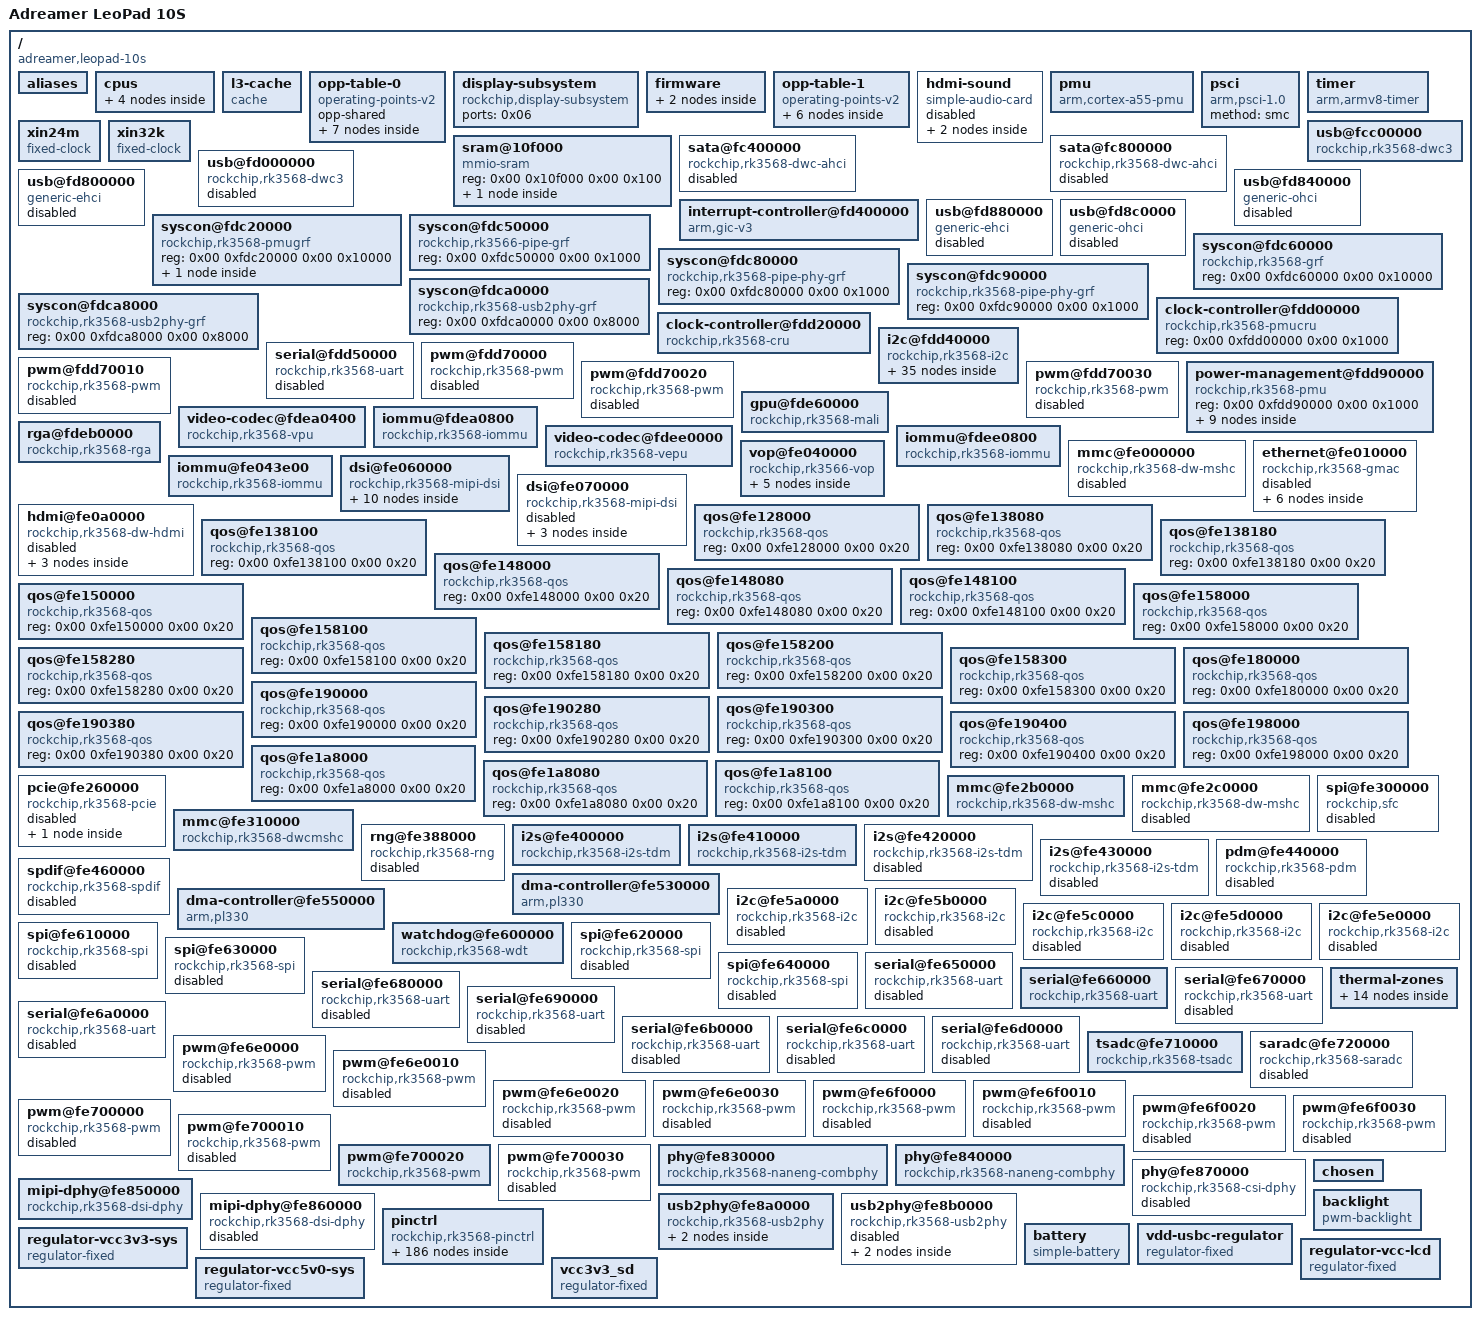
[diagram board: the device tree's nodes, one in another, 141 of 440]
/dts-v1/;

/ {
	interrupt-parent = <0x01>;
	#address-cells = <0x02>;
	#size-cells = <0x02>;
	compatible = "adreamer,leopad-10s\0rockchip,rk3566";
	model = "Adreamer LeoPad 10S";

	aliases {
		gpio0 = "/pinctrl/gpio@fdd60000";
		gpio1 = "/pinctrl/gpio@fe740000";
		gpio2 = "/pinctrl/gpio@fe750000";
		gpio3 = "/pinctrl/gpio@fe760000";
		gpio4 = "/pinctrl/gpio@fe770000";
		i2c0 = "/i2c@fdd40000";
		i2c1 = "/i2c@fe5a0000";
		i2c2 = "/i2c@fe5b0000";
		i2c3 = "/i2c@fe5c0000";
		i2c4 = "/i2c@fe5d0000";
		i2c5 = "/i2c@fe5e0000";
		serial0 = "/serial@fdd50000";
		serial1 = "/serial@fe650000";
		serial2 = "/serial@fe660000";
		serial3 = "/serial@fe670000";
		serial4 = "/serial@fe680000";
		serial5 = "/serial@fe690000";
		serial6 = "/serial@fe6a0000";
		serial7 = "/serial@fe6b0000";
		serial8 = "/serial@fe6c0000";
		serial9 = "/serial@fe6d0000";
		spi0 = "/spi@fe610000";
		spi1 = "/spi@fe620000";
		spi2 = "/spi@fe630000";
		spi3 = "/spi@fe640000";
		mmc0 = "/mmc@fe2b0000";
		mmc1 = "/mmc@fe310000";
	};

	cpus {
		#address-cells = <0x02>;
		#size-cells = <0x00>;

		cpu@0 {
			device_type = "cpu";
			compatible = "arm,cortex-a55";
			reg = <0x00 0x00>;
			clocks = <0x02 0x00>;
			#cooling-cells = <0x02>;
			enable-method = "psci";
			operating-points-v2 = <0x03>;
			i-cache-size = <0x8000>;
			i-cache-line-size = <0x40>;
			i-cache-sets = <0x80>;
			d-cache-size = <0x8000>;
			d-cache-line-size = <0x40>;
			d-cache-sets = <0x80>;
			next-level-cache = <0x04>;
			cpu-supply = <0x05>;
			phandle = <0x0a>;
		};

		cpu@100 {
			device_type = "cpu";
			compatible = "arm,cortex-a55";
			reg = <0x00 0x100>;
			#cooling-cells = <0x02>;
			enable-method = "psci";
			operating-points-v2 = <0x03>;
			i-cache-size = <0x8000>;
			i-cache-line-size = <0x40>;
			i-cache-sets = <0x80>;
			d-cache-size = <0x8000>;
			d-cache-line-size = <0x40>;
			d-cache-sets = <0x80>;
			next-level-cache = <0x04>;
			cpu-supply = <0x05>;
			phandle = <0x0b>;
		};

		cpu@200 {
			device_type = "cpu";
			compatible = "arm,cortex-a55";
			reg = <0x00 0x200>;
			#cooling-cells = <0x02>;
			enable-method = "psci";
			operating-points-v2 = <0x03>;
			i-cache-size = <0x8000>;
			i-cache-line-size = <0x40>;
			i-cache-sets = <0x80>;
			d-cache-size = <0x8000>;
			d-cache-line-size = <0x40>;
			d-cache-sets = <0x80>;
			next-level-cache = <0x04>;
			cpu-supply = <0x05>;
			phandle = <0x0c>;
		};

		cpu@300 {
			device_type = "cpu";
			compatible = "arm,cortex-a55";
			reg = <0x00 0x300>;
			#cooling-cells = <0x02>;
			enable-method = "psci";
			operating-points-v2 = <0x03>;
			i-cache-size = <0x8000>;
			i-cache-line-size = <0x40>;
			i-cache-sets = <0x80>;
			d-cache-size = <0x8000>;
			d-cache-line-size = <0x40>;
			d-cache-sets = <0x80>;
			next-level-cache = <0x04>;
			cpu-supply = <0x05>;
			phandle = <0x0d>;
		};
	};

	l3-cache {
		compatible = "cache";
		cache-level = <0x02>;
		cache-unified;
		cache-size = <0x80000>;
		cache-line-size = <0x40>;
		cache-sets = <0x200>;
		phandle = <0x04>;
	};

	opp-table-0 {
		compatible = "operating-points-v2";
		opp-shared;
		phandle = <0x03>;

		opp-408000000 {
			opp-hz = <0x00 0x18519600>;
			opp-microvolt = <0xdbba0 0xdbba0 0x118c30>;
			clock-latency-ns = <0x9c40>;
		};

		opp-600000000 {
			opp-hz = <0x00 0x23c34600>;
			opp-microvolt = <0xdbba0 0xdbba0 0x118c30>;
		};

		opp-816000000 {
			opp-hz = <0x00 0x30a32c00>;
			opp-microvolt = <0xdbba0 0xdbba0 0x118c30>;
			opp-suspend;
		};

		opp-1104000000 {
			opp-hz = <0x00 0x41cdb400>;
			opp-microvolt = <0xdbba0 0xdbba0 0x118c30>;
		};

		opp-1416000000 {
			opp-hz = <0x00 0x54667200>;
			opp-microvolt = <0xdbba0 0xdbba0 0x118c30>;
		};

		opp-1608000000 {
			opp-hz = <0x00 0x5fd82200>;
			opp-microvolt = <0xee098 0xee098 0x118c30>;
		};

		opp-1800000000 {
			opp-hz = <0x00 0x6b49d200>;
			opp-microvolt = <0x100590 0x100590 0x118c30>;
		};
	};

	display-subsystem {
		compatible = "rockchip,display-subsystem";
		ports = <0x06>;
	};

	firmware {

		scmi {
			compatible = "arm,scmi-smc";
			arm,smc-id = <0x82000010>;
			shmem = <0x07>;
			#address-cells = <0x01>;
			#size-cells = <0x00>;

			protocol@14 {
				reg = <0x14>;
				#clock-cells = <0x01>;
				phandle = <0x02>;
			};
		};
	};

	opp-table-1 {
		compatible = "operating-points-v2";
		phandle = <0x46>;

		opp-200000000 {
			opp-hz = <0x00 0xbebc200>;
			opp-microvolt = <0xc96a8>;
		};

		opp-300000000 {
			opp-hz = <0x00 0x11e1a300>;
			opp-microvolt = <0xc96a8>;
		};

		opp-400000000 {
			opp-hz = <0x00 0x17d78400>;
			opp-microvolt = <0xc96a8>;
		};

		opp-600000000 {
			opp-hz = <0x00 0x23c34600>;
			opp-microvolt = <0xc96a8>;
		};

		opp-700000000 {
			opp-hz = <0x00 0x29b92700>;
			opp-microvolt = <0xdbba0>;
		};

		opp-800000000 {
			opp-hz = <0x00 0x2faf0800>;
			opp-microvolt = <0xf4240>;
		};
	};

	hdmi-sound {
		compatible = "simple-audio-card";
		simple-audio-card,name = "HDMI";
		simple-audio-card,format = "i2s";
		simple-audio-card,mclk-fs = <0x100>;
		status = "disabled";

		simple-audio-card,codec {
			sound-dai = <0x08>;
		};

		simple-audio-card,cpu {
			sound-dai = <0x09>;
		};
	};

	pmu {
		compatible = "arm,cortex-a55-pmu";
		interrupts = <0x00 0xe4 0x04 0x00 0xe5 0x04 0x00 0xe6 0x04 0x00 0xe7 0x04>;
		interrupt-affinity = <0x0a 0x0b 0x0c 0x0d>;
	};

	psci {
		compatible = "arm,psci-1.0";
		method = "smc";
	};

	timer {
		compatible = "arm,armv8-timer";
		interrupts = <0x01 0x0d 0x04 0x01 0x0e 0x04 0x01 0x0b 0x04 0x01 0x0a 0x04>;
		arm,no-tick-in-suspend;
	};

	xin24m {
		compatible = "fixed-clock";
		clock-frequency = <0x16e3600>;
		clock-output-names = "xin24m";
		#clock-cells = <0x00>;
		phandle = <0x1e>;
	};

	xin32k {
		compatible = "fixed-clock";
		clock-frequency = <0x8000>;
		clock-output-names = "xin32k";
		pinctrl-0 = <0x0e>;
		pinctrl-names = "default";
		#clock-cells = <0x00>;
	};

	sram@10f000 {
		compatible = "mmio-sram";
		reg = <0x00 0x10f000 0x00 0x100>;
		#address-cells = <0x01>;
		#size-cells = <0x01>;
		ranges = <0x00 0x00 0x10f000 0x100>;

		sram@0 {
			compatible = "arm,scmi-shmem";
			reg = <0x00 0x100>;
			phandle = <0x07>;
		};
	};

	sata@fc400000 {
		compatible = "rockchip,rk3568-dwc-ahci\0snps,dwc-ahci";
		reg = <0x00 0xfc400000 0x00 0x1000>;
		clocks = <0x0f 0x9b 0x0f 0x9c 0x0f 0x9d>;
		clock-names = "sata\0pmalive\0rxoob";
		interrupts = <0x00 0x5f 0x04>;
		phys = <0x10 0x01>;
		phy-names = "sata-phy";
		ports-implemented = <0x01>;
		power-domains = <0x11 0x0f>;
		status = "disabled";
	};

	sata@fc800000 {
		compatible = "rockchip,rk3568-dwc-ahci\0snps,dwc-ahci";
		reg = <0x00 0xfc800000 0x00 0x1000>;
		clocks = <0x0f 0xa0 0x0f 0xa1 0x0f 0xa2>;
		clock-names = "sata\0pmalive\0rxoob";
		interrupts = <0x00 0x60 0x04>;
		phys = <0x12 0x01>;
		phy-names = "sata-phy";
		ports-implemented = <0x01>;
		power-domains = <0x11 0x0f>;
		status = "disabled";
	};

	usb@fcc00000 {
		compatible = "rockchip,rk3568-dwc3\0snps,dwc3";
		reg = <0x00 0xfcc00000 0x00 0x400000>;
		interrupts = <0x00 0xa9 0x04>;
		clocks = <0x0f 0xa6 0x0f 0xa7 0x0f 0xa5>;
		clock-names = "ref_clk\0suspend_clk\0bus_clk";
		dr_mode = "host";
		phy_type = "utmi_wide";
		power-domains = <0x11 0x0f>;
		resets = <0x0f 0x94>;
		snps,dis_u2_susphy_quirk;
		status = "okay";
		phys = <0x13>;
		phy-names = "usb2-phy";
		extcon = <0x14>;
		maximum-speed = "high-speed";
	};

	usb@fd000000 {
		compatible = "rockchip,rk3568-dwc3\0snps,dwc3";
		reg = <0x00 0xfd000000 0x00 0x400000>;
		interrupts = <0x00 0xaa 0x04>;
		clocks = <0x0f 0xa9 0x0f 0xaa 0x0f 0xa8>;
		clock-names = "ref_clk\0suspend_clk\0bus_clk";
		dr_mode = "host";
		phys = <0x15>;
		phy-names = "usb2-phy";
		phy_type = "utmi_wide";
		power-domains = <0x11 0x0f>;
		resets = <0x0f 0x95>;
		snps,dis_u2_susphy_quirk;
		status = "disabled";
	};

	interrupt-controller@fd400000 {
		compatible = "arm,gic-v3";
		reg = <0x00 0xfd400000 0x00 0x10000 0x00 0xfd460000 0x00 0x80000>;
		interrupts = <0x01 0x09 0x04>;
		interrupt-controller;
		#interrupt-cells = <0x03>;
		mbi-alias = <0x00 0xfd410000>;
		mbi-ranges = <0x128 0x18>;
		msi-controller;
		phandle = <0x01>;
	};

	usb@fd800000 {
		compatible = "generic-ehci";
		reg = <0x00 0xfd800000 0x00 0x40000>;
		interrupts = <0x00 0x82 0x04>;
		clocks = <0x0f 0xbd 0x0f 0xbe 0x0f 0xbc>;
		phys = <0x16>;
		phy-names = "usb";
		status = "disabled";
	};

	usb@fd840000 {
		compatible = "generic-ohci";
		reg = <0x00 0xfd840000 0x00 0x40000>;
		interrupts = <0x00 0x83 0x04>;
		clocks = <0x0f 0xbd 0x0f 0xbe 0x0f 0xbc>;
		phys = <0x16>;
		phy-names = "usb";
		status = "disabled";
	};

	usb@fd880000 {
		compatible = "generic-ehci";
		reg = <0x00 0xfd880000 0x00 0x40000>;
		interrupts = <0x00 0x85 0x04>;
		clocks = <0x0f 0xbf 0x0f 0xc0 0x0f 0xbc>;
		phys = <0x17>;
		phy-names = "usb";
		status = "disabled";
	};

	usb@fd8c0000 {
		compatible = "generic-ohci";
		reg = <0x00 0xfd8c0000 0x00 0x40000>;
		interrupts = <0x00 0x86 0x04>;
		clocks = <0x0f 0xbf 0x0f 0xc0 0x0f 0xbc>;
		phys = <0x17>;
		phy-names = "usb";
		status = "disabled";
	};

	syscon@fdc20000 {
		compatible = "rockchip,rk3568-pmugrf\0syscon\0simple-mfd";
		reg = <0x00 0xfdc20000 0x00 0x10000>;
		phandle = <0xa9>;

		io-domains {
			compatible = "rockchip,rk3568-pmu-io-voltage-domain";
			status = "okay";
			pmuio1-supply = <0x18>;
			pmuio2-supply = <0x18>;
			vccio1-supply = <0x19>;
			vccio2-supply = <0x1a>;
			vccio3-supply = <0x1b>;
			vccio4-supply = <0x1a>;
			vccio5-supply = <0x1c>;
			vccio6-supply = <0x1d>;
			vccio7-supply = <0x1c>;
		};
	};

	syscon@fdc50000 {
		reg = <0x00 0xfdc50000 0x00 0x1000>;
		compatible = "rockchip,rk3566-pipe-grf\0syscon";
		phandle = <0xa4>;
	};

	syscon@fdc60000 {
		compatible = "rockchip,rk3568-grf\0syscon\0simple-mfd";
		reg = <0x00 0xfdc60000 0x00 0x10000>;
		phandle = <0x20>;
	};

	syscon@fdc80000 {
		compatible = "rockchip,rk3568-pipe-phy-grf\0syscon";
		reg = <0x00 0xfdc80000 0x00 0x1000>;
		phandle = <0xa5>;
	};

	syscon@fdc90000 {
		compatible = "rockchip,rk3568-pipe-phy-grf\0syscon";
		reg = <0x00 0xfdc90000 0x00 0x1000>;
		phandle = <0xa6>;
	};

	syscon@fdca0000 {
		compatible = "rockchip,rk3568-usb2phy-grf\0syscon";
		reg = <0x00 0xfdca0000 0x00 0x8000>;
		phandle = <0xa7>;
	};

	syscon@fdca8000 {
		compatible = "rockchip,rk3568-usb2phy-grf\0syscon";
		reg = <0x00 0xfdca8000 0x00 0x8000>;
		phandle = <0xa8>;
	};

	clock-controller@fdd00000 {
		compatible = "rockchip,rk3568-pmucru";
		reg = <0x00 0xfdd00000 0x00 0x1000>;
		#clock-cells = <0x01>;
		#reset-cells = <0x01>;
		phandle = <0x1f>;
	};

	clock-controller@fdd20000 {
		compatible = "rockchip,rk3568-cru";
		reg = <0x00 0xfdd20000 0x00 0x1000>;
		clocks = <0x1e>;
		clock-names = "xin24m";
		#clock-cells = <0x01>;
		#reset-cells = <0x01>;
		assigned-clocks = <0x1f 0x05 0x0f 0x04 0x1f 0x01 0x0f 0x05>;
		assigned-clock-rates = <0x8000 0x47868c00 0xbebc200 0xcdfe600>;
		assigned-clock-parents = <0x1f 0x08>;
		rockchip,grf = <0x20>;
		phandle = <0x0f>;
	};

	i2c@fdd40000 {
		compatible = "rockchip,rk3568-i2c\0rockchip,rk3399-i2c";
		reg = <0x00 0xfdd40000 0x00 0x1000>;
		interrupts = <0x00 0x2e 0x04>;
		clocks = <0x1f 0x07 0x1f 0x2d>;
		clock-names = "i2c\0pclk";
		pinctrl-0 = <0x21>;
		pinctrl-names = "default";
		#address-cells = <0x01>;
		#size-cells = <0x00>;
		status = "okay";

		regulator@40 {
			compatible = "silergy,syr827";
			reg = <0x40>;
			regulator-compatible = "fan53555-reg";
			fcs,suspend-voltage-selector = <0x01>;
			regulator-name = "vdd_cpu";
			regulator-min-microvolt = <0xadf34>;
			regulator-max-microvolt = <0x1535b0>;
			regulator-ramp-delay = <0x8fc>;
			regulator-always-on;
			regulator-boot-on;
			vin-supply = <0x22>;
			phandle = <0x05>;

			regulator-state-mem {
				regulator-off-in-suspend;
			};
		};

		pmic@20 {
			compatible = "rockchip,rk817";
			reg = <0x20>;
			interrupt-parent = <0x23>;
			interrupts = <0x03 0x08>;
			clock-output-names = "rk808-clkout1\0rk808-clkout2";
			#clock-cells = <0x01>;
			pinctrl-names = "default";
			pinctrl-0 = <0x24 0x25>;
			assigned-clocks = <0x0f 0x48>;
			assigned-clock-parents = <0x0f 0x196>;
			clock-names = "mclk";
			clocks = <0x0f 0x48>;
			rockchip,system-power-controller;
			#sound-dai-cells = <0x00>;
			wakeup-source;
			vcc1-supply = <0x26>;
			vcc2-supply = <0x26>;
			vcc3-supply = <0x26>;
			vcc4-supply = <0x26>;
			vcc5-supply = <0x26>;
			vcc6-supply = <0x26>;
			vcc7-supply = <0x26>;
			vcc8-supply = <0x26>;
			vcc9-supply = <0x27>;

			regulators {

				DCDC_REG1 {
					regulator-always-on;
					regulator-boot-on;
					regulator-min-microvolt = <0x7a120>;
					regulator-max-microvolt = <0x149970>;
					regulator-ramp-delay = <0x1771>;
					regulator-initial-mode = <0x02>;
					regulator-name = "vdd_logic";

					regulator-state-mem {
						regulator-on-in-suspend;
						regulator-suspend-microvolt = <0xdbba0>;
					};
				};

				DCDC_REG2 {
					regulator-always-on;
					regulator-boot-on;
					regulator-min-microvolt = <0x7a120>;
					regulator-max-microvolt = <0x149970>;
					regulator-ramp-delay = <0x1771>;
					regulator-initial-mode = <0x02>;
					regulator-name = "vdd_gpu";
					phandle = <0x47>;

					regulator-state-mem {
						regulator-off-in-suspend;
					};
				};

				DCDC_REG3 {
					regulator-always-on;
					regulator-boot-on;
					regulator-initial-mode = <0x02>;
					regulator-name = "vcc_ddr";

					regulator-state-mem {
						regulator-on-in-suspend;
					};
				};

				DCDC_REG4 {
					regulator-always-on;
					regulator-boot-on;
					regulator-min-microvolt = <0x325aa0>;
					regulator-max-microvolt = <0x325aa0>;
					regulator-initial-mode = <0x02>;
					regulator-name = "vcc_3v3";
					phandle = <0x1c>;

					regulator-state-mem {
						regulator-off-in-suspend;
					};
				};

				LDO_REG1 {
					regulator-always-on;
					regulator-boot-on;
					regulator-min-microvolt = <0x1b7740>;
					regulator-max-microvolt = <0x1b7740>;
					regulator-name = "vcca1v8_pmu";

					regulator-state-mem {
						regulator-on-in-suspend;
						regulator-suspend-microvolt = <0x1b7740>;
					};
				};

				LDO_REG2 {
					regulator-always-on;
					regulator-boot-on;
					regulator-min-microvolt = <0xdbba0>;
					regulator-max-microvolt = <0xdbba0>;
					regulator-name = "vdda_0v9";

					regulator-state-mem {
						regulator-off-in-suspend;
					};
				};

				LDO_REG3 {
					regulator-always-on;
					regulator-boot-on;
					regulator-min-microvolt = <0xdbba0>;
					regulator-max-microvolt = <0xdbba0>;
					regulator-name = "vdda0v9_pmu";

					regulator-state-mem {
						regulator-on-in-suspend;
						regulator-suspend-microvolt = <0xdbba0>;
					};
				};

				LDO_REG4 {
					regulator-always-on;
					regulator-boot-on;
					regulator-min-microvolt = <0x325aa0>;
					regulator-max-microvolt = <0x325aa0>;
					regulator-name = "vccio_acodec";
					phandle = <0x19>;

					regulator-state-mem {
						regulator-off-in-suspend;
					};
				};

				LDO_REG5 {
					regulator-always-on;
					regulator-boot-on;
					regulator-min-microvolt = <0x1b7740>;
					regulator-max-microvolt = <0x325aa0>;
					regulator-name = "vccio_sd";
					phandle = <0x1b>;

					regulator-state-mem {
						regulator-off-in-suspend;
					};
				};

				LDO_REG6 {
					regulator-always-on;
					regulator-boot-on;
					regulator-min-microvolt = <0x325aa0>;
					regulator-max-microvolt = <0x325aa0>;
					regulator-name = "vcc3v3_pmu";
					phandle = <0x18>;

					regulator-state-mem {
						regulator-on-in-suspend;
						regulator-suspend-microvolt = <0x325aa0>;
					};
				};

				LDO_REG7 {
					regulator-always-on;
					regulator-boot-on;
					regulator-min-microvolt = <0x1b7740>;
					regulator-max-microvolt = <0x1b7740>;
					regulator-name = "vcc_1v8";
					phandle = <0x1a>;

					regulator-state-mem {
						regulator-off-in-suspend;
					};
				};

				LDO_REG8 {
					regulator-always-on;
					regulator-boot-on;
					regulator-min-microvolt = <0x1b7740>;
					regulator-max-microvolt = <0x1b7740>;
					regulator-name = "vcc1v8_dvp";
					phandle = <0x1d>;

					regulator-state-mem {
						regulator-off-in-suspend;
					};
				};

				LDO_REG9 {
					regulator-always-on;
					regulator-boot-on;
					regulator-min-microvolt = <0x2ab980>;
					regulator-max-microvolt = <0x2ab980>;
					regulator-name = "vcc2v8_dvp";

					regulator-state-mem {
						regulator-off-in-suspend;
					};
				};

				BOOST {
					regulator-min-microvolt = <0x4f5880>;
					regulator-max-microvolt = <0x5265c0>;
					regulator-name = "boost";
					phandle = <0x27>;

					regulator-state-mem {
						regulator-off-in-suspend;
					};
				};

				OTG_SWITCH {
					regulator-name = "otg_switch";

					regulator-state-mem {
						regulator-off-in-suspend;
					};
				};
			};

			charger {
				monitored-battery = <0x28>;
				rockchip,resistor-sense-micro-ohms = <0x2710>;
				rockchip,sleep-enter-current-microamp = <0x249f0>;
				rockchip,sleep-filter-current-microamp = <0x186a0>;
			};
		};
	};

	serial@fdd50000 {
		compatible = "rockchip,rk3568-uart\0snps,dw-apb-uart";
		reg = <0x00 0xfdd50000 0x00 0x100>;
		interrupts = <0x00 0x74 0x04>;
		clocks = <0x1f 0x0b 0x1f 0x2c>;
		clock-names = "baudclk\0apb_pclk";
		dmas = <0x29 0x00 0x29 0x01>;
		pinctrl-0 = <0x2a>;
		pinctrl-names = "default";
		reg-io-width = <0x04>;
		reg-shift = <0x02>;
		status = "disabled";
	};

	pwm@fdd70000 {
		compatible = "rockchip,rk3568-pwm\0rockchip,rk3328-pwm";
		reg = <0x00 0xfdd70000 0x00 0x10>;
		clocks = <0x1f 0x0d 0x1f 0x30>;
		clock-names = "pwm\0pclk";
		pinctrl-0 = <0x2b>;
		pinctrl-names = "default";
		#pwm-cells = <0x03>;
		status = "disabled";
	};

	pwm@fdd70010 {
		compatible = "rockchip,rk3568-pwm\0rockchip,rk3328-pwm";
		reg = <0x00 0xfdd70010 0x00 0x10>;
		clocks = <0x1f 0x0d 0x1f 0x30>;
		clock-names = "pwm\0pclk";
		pinctrl-0 = <0x2c>;
		pinctrl-names = "default";
		#pwm-cells = <0x03>;
		status = "disabled";
	};

	pwm@fdd70020 {
		compatible = "rockchip,rk3568-pwm\0rockchip,rk3328-pwm";
		reg = <0x00 0xfdd70020 0x00 0x10>;
		clocks = <0x1f 0x0d 0x1f 0x30>;
		clock-names = "pwm\0pclk";
		pinctrl-0 = <0x2d>;
		pinctrl-names = "default";
		#pwm-cells = <0x03>;
		status = "disabled";
	};

	pwm@fdd70030 {
		compatible = "rockchip,rk3568-pwm\0rockchip,rk3328-pwm";
		reg = <0x00 0xfdd70030 0x00 0x10>;
		clocks = <0x1f 0x0d 0x1f 0x30>;
		clock-names = "pwm\0pclk";
		pinctrl-0 = <0x2e>;
		pinctrl-names = "default";
		#pwm-cells = <0x03>;
		status = "disabled";
	};

	power-management@fdd90000 {
		compatible = "rockchip,rk3568-pmu\0syscon\0simple-mfd";
		reg = <0x00 0xfdd90000 0x00 0x1000>;

		power-controller {
			compatible = "rockchip,rk3568-power-controller";
			#power-domain-cells = <0x01>;
			#address-cells = <0x01>;
			#size-cells = <0x00>;
			phandle = <0x11>;

			power-domain@7 {
				reg = <0x07>;
				clocks = <0x0f 0x19 0x0f 0x1a>;
				pm_qos = <0x2f>;
				#power-domain-cells = <0x00>;
			};

			power-domain@8 {
				reg = <0x08>;
				clocks = <0x0f 0xcc 0x0f 0xcd>;
				pm_qos = <0x30 0x31 0x32>;
				#power-domain-cells = <0x00>;
			};

			power-domain@9 {
				reg = <0x09>;
				clocks = <0x0f 0xda 0x0f 0xdb 0x0f 0xdc>;
				pm_qos = <0x33 0x34 0x35>;
				#power-domain-cells = <0x00>;
			};

			power-domain@10 {
				reg = <0x0a>;
				clocks = <0x0f 0xf1 0x0f 0xf2>;
				pm_qos = <0x36 0x37 0x38 0x39 0x3a 0x3b>;
				#power-domain-cells = <0x00>;
			};

			power-domain@11 {
				reg = <0x0b>;
				clocks = <0x0f 0xed>;
				pm_qos = <0x3c>;
				#power-domain-cells = <0x00>;
			};

			power-domain@13 {
				clocks = <0x0f 0x107>;
				reg = <0x0d>;
				pm_qos = <0x3d>;
				#power-domain-cells = <0x00>;
			};

			power-domain@14 {
				reg = <0x0e>;
				clocks = <0x0f 0x102>;
				pm_qos = <0x3e 0x3f 0x40>;
				#power-domain-cells = <0x00>;
			};

			power-domain@15 {
				reg = <0x0f>;
				clocks = <0x0f 0x7f>;
				pm_qos = <0x41 0x42 0x43 0x44 0x45>;
				#power-domain-cells = <0x00>;
			};
		};
	};

	gpu@fde60000 {
		compatible = "rockchip,rk3568-mali\0arm,mali-bifrost";
		reg = <0x00 0xfde60000 0x00 0x4000>;
		interrupts = <0x00 0x28 0x04 0x00 0x29 0x04 0x00 0x27 0x04>;
		interrupt-names = "job\0mmu\0gpu";
		clocks = <0x02 0x01 0x0f 0x1b>;
		clock-names = "gpu\0bus";
		#cooling-cells = <0x02>;
		operating-points-v2 = <0x46>;
		power-domains = <0x11 0x07>;
		status = "okay";
		mali-supply = <0x47>;
		phandle = <0x95>;
	};

	video-codec@fdea0400 {
		compatible = "rockchip,rk3568-vpu";
		reg = <0x00 0xfdea0000 0x00 0x800>;
		interrupts = <0x00 0x8b 0x04>;
		interrupt-names = "vdpu";
		clocks = <0x0f 0xee 0x0f 0xef>;
		clock-names = "aclk\0hclk";
		iommus = <0x48>;
		power-domains = <0x11 0x0b>;
	};

	iommu@fdea0800 {
		compatible = "rockchip,rk3568-iommu";
		reg = <0x00 0xfdea0800 0x00 0x40>;
		interrupts = <0x00 0x8a 0x04>;
		clock-names = "aclk\0iface";
		clocks = <0x0f 0xee 0x0f 0xef>;
		power-domains = <0x11 0x0b>;
		#iommu-cells = <0x00>;
		phandle = <0x48>;
	};

	rga@fdeb0000 {
		compatible = "rockchip,rk3568-rga\0rockchip,rk3288-rga";
		reg = <0x00 0xfdeb0000 0x00 0x180>;
		interrupts = <0x00 0x5a 0x04>;
		clocks = <0x0f 0xf3 0x0f 0xf4 0x0f 0xf5>;
		clock-names = "aclk\0hclk\0sclk";
		resets = <0x0f 0x126 0x0f 0x124 0x0f 0x125>;
		reset-names = "core\0axi\0ahb";
		power-domains = <0x11 0x0a>;
	};

	video-codec@fdee0000 {
		compatible = "rockchip,rk3568-vepu";
		reg = <0x00 0xfdee0000 0x00 0x800>;
		interrupts = <0x00 0x40 0x04>;
		clocks = <0x0f 0xfd 0x0f 0xfe>;
		clock-names = "aclk\0hclk";
		iommus = <0x49>;
		power-domains = <0x11 0x0a>;
	};

	iommu@fdee0800 {
		compatible = "rockchip,rk3568-iommu";
		reg = <0x00 0xfdee0800 0x00 0x40>;
		interrupts = <0x00 0x3f 0x04>;
		clocks = <0x0f 0xfd 0x0f 0xfe>;
		clock-names = "aclk\0iface";
		power-domains = <0x11 0x0a>;
		#iommu-cells = <0x00>;
		phandle = <0x49>;
	};

	mmc@fe000000 {
		compatible = "rockchip,rk3568-dw-mshc\0rockchip,rk3288-dw-mshc";
		reg = <0x00 0xfe000000 0x00 0x4000>;
		interrupts = <0x00 0x64 0x04>;
		clocks = <0x0f 0xc1 0x0f 0xc2 0x0f 0x18e 0x0f 0x18f>;
		clock-names = "biu\0ciu\0ciu-drive\0ciu-sample";
		fifo-depth = <0x100>;
		max-frequency = <0x8f0d180>;
		resets = <0x0f 0xeb>;
		reset-names = "reset";
		status = "disabled";
	};

	ethernet@fe010000 {
		compatible = "rockchip,rk3568-gmac\0snps,dwmac-4.20a";
		reg = <0x00 0xfe010000 0x00 0x10000>;
		interrupts = <0x00 0x20 0x04 0x00 0x1d 0x04>;
		interrupt-names = "macirq\0eth_wake_irq";
		clocks = <0x0f 0x186 0x0f 0x189 0x0f 0x189 0x0f 0xc7 0x0f 0xc3 0x0f 0xc4 0x0f 0x189 0x0f 0xc8>;
		clock-names = "stmmaceth\0mac_clk_rx\0mac_clk_tx\0clk_mac_refout\0aclk_mac\0pclk_mac\0clk_mac_speed\0ptp_ref";
		resets = <0x0f 0xec>;
		reset-names = "stmmaceth";
		rockchip,grf = <0x20>;
		snps,axi-config = <0x4a>;
		snps,mixed-burst;
		snps,mtl-rx-config = <0x4b>;
		snps,mtl-tx-config = <0x4c>;
		snps,tso;
		status = "disabled";

		mdio {
			compatible = "snps,dwmac-mdio";
			#address-cells = <0x01>;
			#size-cells = <0x00>;
		};

		stmmac-axi-config {
			snps,blen = <0x00 0x00 0x00 0x00 0x10 0x08 0x04>;
			snps,rd_osr_lmt = <0x08>;
			snps,wr_osr_lmt = <0x04>;
			phandle = <0x4a>;
		};

		rx-queues-config {
			snps,rx-queues-to-use = <0x01>;
			phandle = <0x4b>;

			queue0 {
			};
		};

		tx-queues-config {
			snps,tx-queues-to-use = <0x01>;
			phandle = <0x4c>;

			queue0 {
			};
		};
	};

	vop@fe040000 {
		reg = <0x00 0xfe040000 0x00 0x3000 0x00 0xfe044000 0x00 0x1000>;
		reg-names = "vop\0gamma-lut";
		interrupts = <0x00 0x94 0x04>;
		clocks = <0x0f 0xdd 0x0f 0xde 0x0f 0xdf 0x0f 0xe0 0x0f 0xe1>;
		clock-names = "aclk\0hclk\0dclk_vp0\0dclk_vp1\0dclk_vp2";
		iommus = <0x4d>;
		power-domains = <0x11 0x09>;
		rockchip,grf = <0x20>;
		status = "okay";
		compatible = "rockchip,rk3566-vop";
		assigned-clocks = <0x0f 0xdf 0x0f 0xe0>;
		assigned-clock-parents = <0x1f 0x02 0x0f 0x05>;

		ports {
			#address-cells = <0x01>;
			#size-cells = <0x00>;
			phandle = <0x06>;

			port@0 {
				reg = <0x00>;
				#address-cells = <0x01>;
				#size-cells = <0x00>;
			};

			port@1 {
				reg = <0x01>;
				#address-cells = <0x01>;
				#size-cells = <0x00>;

				endpoint@4 {
					reg = <0x04>;
					remote-endpoint = <0x4e>;
					phandle = <0x50>;
				};
			};

			port@2 {
				reg = <0x02>;
				#address-cells = <0x01>;
				#size-cells = <0x00>;
			};
		};
	};

	iommu@fe043e00 {
		compatible = "rockchip,rk3568-iommu";
		reg = <0x00 0xfe043e00 0x00 0x100 0x00 0xfe043f00 0x00 0x100>;
		interrupts = <0x00 0x94 0x04>;
		clocks = <0x0f 0xdd 0x0f 0xde>;
		clock-names = "aclk\0iface";
		#iommu-cells = <0x00>;
		power-domains = <0x11 0x09>;
		status = "okay";
		phandle = <0x4d>;
	};

	dsi@fe060000 {
		compatible = "rockchip,rk3568-mipi-dsi\0snps,dw-mipi-dsi";
		reg = <0x00 0xfe060000 0x00 0x10000>;
		interrupts = <0x00 0x44 0x04>;
		clock-names = "pclk";
		clocks = <0x0f 0xe8>;
		phy-names = "dphy";
		phys = <0x4f>;
		power-domains = <0x11 0x09>;
		reset-names = "apb";
		resets = <0x0f 0x110>;
		rockchip,grf = <0x20>;
		status = "okay";

		ports {
			#address-cells = <0x01>;
			#size-cells = <0x00>;

			port@0 {
				reg = <0x00>;

				endpoint {
					remote-endpoint = <0x50>;
					phandle = <0x4e>;
				};
			};

			port@1 {
				reg = <0x01>;

				endpoint {
					remote-endpoint = <0x51>;
					phandle = <0x58>;
				};
			};
		};

		panel@0 {
			compatible = "simple-panel-dsi";
			reg = <0x00>;
			backlight = <0x52>;
			enable-gpios = <0x53 0x09 0x00>;
			reset-gpios = <0x53 0x13 0x01>;
			pinctrl-names = "default";
			pinctrl-0 = <0x54 0x55>;
			power-supply = <0x56>;
			prepare-delay-ms = <0x14>;
			reset-delay-ms = <0x14>;
			init-delay-ms = <0x14>;
			enable-delay-ms = <0x78>;
			disable-delay-ms = <0x14>;
			unprepare-delay-ms = <0x14>;
			width-mm = <0x87>;
			height-mm = <0xd8>;
			dsi,flags = <0xa03>;
			dsi,format = <0x00>;
			dsi,lanes = <0x04>;
			panel-init-sequence = [39 00 04 ff 98 81 03 15 00 02 01 00 15 00 02 02 00 15 00 02 03 53 15 00 02 04 53 15 00 02 05 13 15 00 02 06 04 15 00 02 07 02 15 00 02 08 02 15 00 02 09 00 15 00 02 0a 00 15 00 02 0b 00 15 00 02 0c 00 15 00 02 0d 00 15 00 02 0e 00 15 00 02 0f 00 15 00 02 10 00 15 00 02 11 00 15 00 02 12 00 15 00 02 13 00 15 00 02 14 00 15 00 02 15 05 15 00 02 16 05 15 00 02 17 03 15 00 02 18 03 15 00 02 19 00 15 00 02 1a 00 15 00 02 1b 00 15 00 02 1c 00 15 00 02 1d 00 15 00 02 1e c0 15 00 02 1f 00 15 00 02 20 02 15 00 02 21 09 15 00 02 22 00 15 00 02 23 00 15 00 02 24 00 15 00 02 25 00 15 00 02 26 00 15 00 02 27 00 15 00 02 28 55 15 00 02 29 03 15 00 02 2a 00 15 00 02 2b 00 15 00 02 2c 00 15 00 02 2d 00 15 00 02 2e 00 15 00 02 2f 00 15 00 02 30 00 15 00 02 31 00 15 00 02 32 00 15 00 02 33 00 15 00 02 34 00 15 00 02 35 00 15 00 02 36 00 15 00 02 37 00 15 00 02 38 3c 15 00 02 39 00 15 00 02 3a 00 15 00 02 3b 00 15 00 02 3c 00 15 00 02 3d 00 15 00 02 3e 00 15 00 02 3f 00 15 00 02 40 00 15 00 02 41 00 15 00 02 42 00 15 00 02 43 00 15 00 02 44 00 15 00 02 50 01 15 00 02 51 23 15 00 02 52 45 15 00 02 53 67 15 00 02 54 89 15 00 02 55 ab 15 00 02 56 01 15 00 02 57 23 15 00 02 58 45 15 00 02 59 67 15 00 02 5a 89 15 00 02 5b ab 15 00 02 5c cd 15 00 02 5d ef 15 00 02 5e 01 15 00 02 5f 0a 15 00 02 60 02 15 00 02 61 02 15 00 02 62 08 15 00 02 63 15 15 00 02 64 14 15 00 02 65 02 15 00 02 66 11 15 00 02 67 10 15 00 02 68 02 15 00 02 69 0f 15 00 02 6a 0e 15 00 02 6b 02 15 00 02 6c 0d 15 00 02 6d 0c 15 00 02 6e 06 15 00 02 6f 02 15 00 02 70 02 15 00 02 71 02 15 00 02 72 02 15 00 02 73 02 15 00 02 74 02 15 00 02 75 0a 15 00 02 76 02 15 00 02 77 02 15 00 02 78 06 15 00 02 79 15 15 00 02 7a 14 15 00 02 7b 02 15 00 02 7c 10 15 00 02 7d 11 15 00 02 7e 02 15 00 02 7f 0c 15 00 02 80 0d 15 00 02 81 02 15 00 02 82 0e 15 00 02 83 0f 15 00 02 84 08 15 00 02 85 02 15 00 02 86 02 15 00 02 87 02 15 00 02 88 02 15 00 02 89 02 15 00 02 8a 02 39 00 04 ff 98 81 04 15 00 02 3b c0 15 00 02 6c 15 15 00 02 6e 30 15 00 02 6f 33 15 00 02 8d 1f 15 00 02 3a 24 15 00 02 35 1f 15 00 02 87 ba 15 00 02 26 76 15 00 02 b2 d1 15 00 02 b5 07 15 00 02 88 0b 15 00 02 21 30 39 00 04 ff 98 81 01 15 00 02 22 0a 15 00 02 31 09 15 00 02 40 33 15 00 02 42 44 15 00 02 53 2e 15 00 02 55 88 15 00 02 50 95 15 00 02 51 95 15 00 02 60 43 15 00 02 2e c8 15 00 02 a0 0f 15 00 02 a1 1d 15 00 02 a2 2a 15 00 02 a3 14 15 00 02 a4 16 15 00 02 a5 29 15 00 02 a6 1d 15 00 02 a7 1e 15 00 02 a8 83 15 00 02 a9 1e 15 00 02 aa 2b 15 00 02 ab 6f 15 00 02 ac 18 15 00 02 ad 17 15 00 02 ae 4c 15 00 02 af 22 15 00 02 b0 27 15 00 02 b1 4d 15 00 02 b2 5c 15 00 02 b3 2b 15 00 02 c0 0f 15 00 02 c1 1d 15 00 02 c2 2a 15 00 02 c3 14 15 00 02 c4 16 15 00 02 c5 29 15 00 02 c6 1d 15 00 02 c7 1e 15 00 02 c8 83 15 00 02 c9 1e 15 00 02 ca 2b 15 00 02 cb 6f 15 00 02 cc 18 15 00 02 cd 17 15 00 02 ce 4c 15 00 02 cf 22 15 00 02 d0 27 15 00 02 d1 4d 15 00 02 d2 5c 15 00 02 d3 2b 39 00 04 ff 98 81 00 15 00 02 35 00 05 78 01 11 05 64 01 29];
			panel-exit-sequence = <0x5010128 0x5030110>;

			display-timings {
				native-mode = <0x57>;

				timing0 {
					clock-frequency = <0x453c9c0>;
					hactive = <0x320>;
					vactive = <0x500>;
					hsync-len = <0x10>;
					hback-porch = <0x3c>;
					hfront-porch = <0x3c>;
					vsync-len = <0x04>;
					vback-porch = <0x0a>;
					vfront-porch = <0x0a>;
					hsync-active = <0x00>;
					vsync-active = <0x00>;
					de-active = <0x00>;
					pixelclk-active = <0x01>;
					phandle = <0x57>;
				};
			};

			port {

				endpoint {
					remote-endpoint = <0x58>;
					phandle = <0x51>;
				};
			};
		};
	};

	dsi@fe070000 {
		compatible = "rockchip,rk3568-mipi-dsi\0snps,dw-mipi-dsi";
		reg = <0x00 0xfe070000 0x00 0x10000>;
		interrupts = <0x00 0x45 0x04>;
		clock-names = "pclk";
		clocks = <0x0f 0xe9>;
		phy-names = "dphy";
		phys = <0x59>;
		power-domains = <0x11 0x09>;
		reset-names = "apb";
		resets = <0x0f 0x111>;
		rockchip,grf = <0x20>;
		status = "disabled";

		ports {
			#address-cells = <0x01>;
			#size-cells = <0x00>;

			port@0 {
				reg = <0x00>;
			};

			port@1 {
				reg = <0x01>;
			};
		};
	};

	hdmi@fe0a0000 {
		compatible = "rockchip,rk3568-dw-hdmi";
		reg = <0x00 0xfe0a0000 0x00 0x20000>;
		interrupts = <0x00 0x2d 0x04>;
		clocks = <0x0f 0xe6 0x0f 0xe7 0x0f 0x193 0x1f 0x28 0x0f 0xda>;
		clock-names = "iahb\0isfr\0cec\0ref";
		pinctrl-names = "default";
		pinctrl-0 = <0x5a 0x5b 0x5c>;
		power-domains = <0x11 0x09>;
		reg-io-width = <0x04>;
		rockchip,grf = <0x20>;
		#sound-dai-cells = <0x00>;
		status = "disabled";
		phandle = <0x08>;

		ports {
			#address-cells = <0x01>;
			#size-cells = <0x00>;

			port@0 {
				reg = <0x00>;
			};

			port@1 {
				reg = <0x01>;
			};
		};
	};

	qos@fe128000 {
		compatible = "rockchip,rk3568-qos\0syscon";
		reg = <0x00 0xfe128000 0x00 0x20>;
		phandle = <0x2f>;
	};

	qos@fe138080 {
		compatible = "rockchip,rk3568-qos\0syscon";
		reg = <0x00 0xfe138080 0x00 0x20>;
		phandle = <0x3e>;
	};

	qos@fe138100 {
		compatible = "rockchip,rk3568-qos\0syscon";
		reg = <0x00 0xfe138100 0x00 0x20>;
		phandle = <0x3f>;
	};

	qos@fe138180 {
		compatible = "rockchip,rk3568-qos\0syscon";
		reg = <0x00 0xfe138180 0x00 0x20>;
		phandle = <0x40>;
	};

	qos@fe148000 {
		compatible = "rockchip,rk3568-qos\0syscon";
		reg = <0x00 0xfe148000 0x00 0x20>;
		phandle = <0x30>;
	};

	qos@fe148080 {
		compatible = "rockchip,rk3568-qos\0syscon";
		reg = <0x00 0xfe148080 0x00 0x20>;
		phandle = <0x31>;
	};

	qos@fe148100 {
		compatible = "rockchip,rk3568-qos\0syscon";
		reg = <0x00 0xfe148100 0x00 0x20>;
		phandle = <0x32>;
	};

	qos@fe150000 {
		compatible = "rockchip,rk3568-qos\0syscon";
		reg = <0x00 0xfe150000 0x00 0x20>;
		phandle = <0x3c>;
	};

	qos@fe158000 {
		compatible = "rockchip,rk3568-qos\0syscon";
		reg = <0x00 0xfe158000 0x00 0x20>;
		phandle = <0x36>;
	};

	qos@fe158100 {
		compatible = "rockchip,rk3568-qos\0syscon";
		reg = <0x00 0xfe158100 0x00 0x20>;
		phandle = <0x37>;
	};

	qos@fe158180 {
		compatible = "rockchip,rk3568-qos\0syscon";
		reg = <0x00 0xfe158180 0x00 0x20>;
		phandle = <0x38>;
	};

	qos@fe158200 {
		compatible = "rockchip,rk3568-qos\0syscon";
		reg = <0x00 0xfe158200 0x00 0x20>;
		phandle = <0x39>;
	};

	qos@fe158280 {
		compatible = "rockchip,rk3568-qos\0syscon";
		reg = <0x00 0xfe158280 0x00 0x20>;
		phandle = <0x3a>;
	};

	qos@fe158300 {
		compatible = "rockchip,rk3568-qos\0syscon";
		reg = <0x00 0xfe158300 0x00 0x20>;
		phandle = <0x3b>;
	};

	qos@fe180000 {
		compatible = "rockchip,rk3568-qos\0syscon";
		reg = <0x00 0xfe180000 0x00 0x20>;
	};

	qos@fe190000 {
		compatible = "rockchip,rk3568-qos\0syscon";
		reg = <0x00 0xfe190000 0x00 0x20>;
		phandle = <0x41>;
	};

	qos@fe190280 {
		compatible = "rockchip,rk3568-qos\0syscon";
		reg = <0x00 0xfe190280 0x00 0x20>;
		phandle = <0x42>;
	};

	qos@fe190300 {
		compatible = "rockchip,rk3568-qos\0syscon";
		reg = <0x00 0xfe190300 0x00 0x20>;
		phandle = <0x43>;
	};

	qos@fe190380 {
		compatible = "rockchip,rk3568-qos\0syscon";
		reg = <0x00 0xfe190380 0x00 0x20>;
		phandle = <0x44>;
	};

	qos@fe190400 {
		compatible = "rockchip,rk3568-qos\0syscon";
		reg = <0x00 0xfe190400 0x00 0x20>;
		phandle = <0x45>;
	};

	qos@fe198000 {
		compatible = "rockchip,rk3568-qos\0syscon";
		reg = <0x00 0xfe198000 0x00 0x20>;
		phandle = <0x3d>;
	};

	qos@fe1a8000 {
		compatible = "rockchip,rk3568-qos\0syscon";
		reg = <0x00 0xfe1a8000 0x00 0x20>;
		phandle = <0x33>;
	};

	qos@fe1a8080 {
		compatible = "rockchip,rk3568-qos\0syscon";
		reg = <0x00 0xfe1a8080 0x00 0x20>;
		phandle = <0x34>;
	};

	qos@fe1a8100 {
		compatible = "rockchip,rk3568-qos\0syscon";
		reg = <0x00 0xfe1a8100 0x00 0x20>;
		phandle = <0x35>;
	};

	pcie@fe260000 {
		compatible = "rockchip,rk3568-pcie";
		reg = <0x03 0xc0000000 0x00 0x400000 0x00 0xfe260000 0x00 0x10000 0x00 0xf4000000 0x00 0x100000>;
		reg-names = "dbi\0apb\0config";
		interrupts = <0x00 0x4b 0x04 0x00 0x4a 0x04 0x00 0x49 0x04 0x00 0x48 0x04 0x00 0x47 0x04>;
		interrupt-names = "sys\0pmc\0msg\0legacy\0err";
		bus-range = <0x00 0x0f>;
		clocks = <0x0f 0x81 0x0f 0x82 0x0f 0x83 0x0f 0x84 0x0f 0x85>;
		clock-names = "aclk_mst\0aclk_slv\0aclk_dbi\0pclk\0aux";
		device_type = "pci";
		#interrupt-cells = <0x01>;
		interrupt-map-mask = <0x00 0x00 0x00 0x07>;
		interrupt-map = <0x00 0x00 0x00 0x01 0x5d 0x00 0x00 0x00 0x00 0x02 0x5d 0x01 0x00 0x00 0x00 0x03 0x5d 0x02 0x00 0x00 0x00 0x04 0x5d 0x03>;
		linux,pci-domain = <0x00>;
		num-ib-windows = <0x06>;
		num-ob-windows = <0x02>;
		max-link-speed = <0x02>;
		msi-map = <0x00 0x01 0x00 0x1000>;
		num-lanes = <0x01>;
		phys = <0x12 0x02>;
		phy-names = "pcie-phy";
		power-domains = <0x11 0x0f>;
		ranges = <0x1000000 0x00 0xf4100000 0x00 0xf4100000 0x00 0x100000 0x2000000 0x00 0xf4200000 0x00 0xf4200000 0x00 0x1e00000 0x3000000 0x00 0x40000000 0x03 0x00 0x00 0x40000000>;
		resets = <0x0f 0xa1>;
		reset-names = "pipe";
		#address-cells = <0x03>;
		#size-cells = <0x02>;
		status = "disabled";

		legacy-interrupt-controller {
			#address-cells = <0x00>;
			#interrupt-cells = <0x01>;
			interrupt-controller;
			interrupt-parent = <0x01>;
			interrupts = <0x00 0x48 0x01>;
			phandle = <0x5d>;
		};
	};

	mmc@fe2b0000 {
		compatible = "rockchip,rk3568-dw-mshc\0rockchip,rk3288-dw-mshc";
		reg = <0x00 0xfe2b0000 0x00 0x4000>;
		interrupts = <0x00 0x62 0x04>;
		clocks = <0x0f 0xb0 0x0f 0xb1 0x0f 0x18a 0x0f 0x18b>;
		clock-names = "biu\0ciu\0ciu-drive\0ciu-sample";
		fifo-depth = <0x100>;
		max-frequency = <0x8f0d180>;
		resets = <0x0f 0xd4>;
		reset-names = "reset";
		status = "okay";
		bus-width = <0x04>;
		cap-mmc-highspeed;
		cap-sd-highspeed;
		disable-wp;
		sd-uhs-sdr104;
		pinctrl-names = "default";
		pinctrl-0 = <0x5e 0x5f 0x60 0x61>;
		vmmc-supply = <0x62>;
		vqmmc-supply = <0x1b>;
	};

	mmc@fe2c0000 {
		compatible = "rockchip,rk3568-dw-mshc\0rockchip,rk3288-dw-mshc";
		reg = <0x00 0xfe2c0000 0x00 0x4000>;
		interrupts = <0x00 0x63 0x04>;
		clocks = <0x0f 0xb2 0x0f 0xb3 0x0f 0x18c 0x0f 0x18d>;
		clock-names = "biu\0ciu\0ciu-drive\0ciu-sample";
		fifo-depth = <0x100>;
		max-frequency = <0x8f0d180>;
		resets = <0x0f 0xd6>;
		reset-names = "reset";
		status = "disabled";
	};

	spi@fe300000 {
		compatible = "rockchip,sfc";
		reg = <0x00 0xfe300000 0x00 0x4000>;
		interrupts = <0x00 0x65 0x04>;
		clocks = <0x0f 0x78 0x0f 0x76>;
		clock-names = "clk_sfc\0hclk_sfc";
		pinctrl-0 = <0x63>;
		pinctrl-names = "default";
		status = "disabled";
	};

	mmc@fe310000 {
		compatible = "rockchip,rk3568-dwcmshc";
		reg = <0x00 0xfe310000 0x00 0x10000>;
		interrupts = <0x00 0x13 0x04>;
		assigned-clocks = <0x0f 0x7b 0x0f 0x7d>;
		assigned-clock-rates = <0xbebc200 0x16e3600>;
		clocks = <0x0f 0x7c 0x0f 0x7a 0x0f 0x79 0x0f 0x7b 0x0f 0x7d>;
		clock-names = "core\0bus\0axi\0block\0timer";
		status = "okay";
		bus-width = <0x08>;
		max-frequency = <0xbebc200>;
		mmc-hs200-1_8v;
		non-removable;
		pinctrl-names = "default";
		pinctrl-0 = <0x64 0x65 0x66 0x67>;
	};

	rng@fe388000 {
		compatible = "rockchip,rk3568-rng";
		reg = <0x00 0xfe388000 0x00 0x4000>;
		clocks = <0x0f 0x70 0x0f 0x6f>;
		clock-names = "core\0ahb";
		resets = <0x0f 0x6d>;
		reset-names = "reset";
		status = "disabled";
	};

	i2s@fe400000 {
		compatible = "rockchip,rk3568-i2s-tdm";
		reg = <0x00 0xfe400000 0x00 0x1000>;
		interrupts = <0x00 0x34 0x04>;
		assigned-clocks = <0x0f 0x3d 0x0f 0x41>;
		assigned-clock-rates = <0x46cf7100 0x46cf7100>;
		clocks = <0x0f 0x3f 0x0f 0x43 0x0f 0x39>;
		clock-names = "mclk_tx\0mclk_rx\0hclk";
		dmas = <0x68 0x00>;
		dma-names = "tx";
		resets = <0x0f 0x50 0x0f 0x51>;
		reset-names = "tx-m\0rx-m";
		rockchip,grf = <0x20>;
		#sound-dai-cells = <0x00>;
		status = "okay";
		phandle = <0x09>;
	};

	i2s@fe410000 {
		compatible = "rockchip,rk3568-i2s-tdm";
		reg = <0x00 0xfe410000 0x00 0x1000>;
		interrupts = <0x00 0x35 0x04>;
		assigned-clocks = <0x0f 0x45 0x0f 0x49>;
		assigned-clock-rates = <0x46cf7100 0x46cf7100>;
		clocks = <0x0f 0x47 0x0f 0x4b 0x0f 0x3a>;
		clock-names = "mclk_tx\0mclk_rx\0hclk";
		dmas = <0x68 0x03 0x68 0x02>;
		dma-names = "rx\0tx";
		resets = <0x0f 0x52 0x0f 0x53>;
		reset-names = "tx-m\0rx-m";
		rockchip,grf = <0x20>;
		pinctrl-names = "default";
		pinctrl-0 = <0x69 0x6a 0x6b 0x6c>;
		#sound-dai-cells = <0x00>;
		status = "okay";
		rockchip,trcm-sync-tx-only;
	};

	i2s@fe420000 {
		compatible = "rockchip,rk3568-i2s-tdm";
		reg = <0x00 0xfe420000 0x00 0x1000>;
		interrupts = <0x00 0x36 0x04>;
		assigned-clocks = <0x0f 0x4d>;
		assigned-clock-rates = <0x46cf7100>;
		clocks = <0x0f 0x4f 0x0f 0x4f 0x0f 0x3b>;
		clock-names = "mclk_tx\0mclk_rx\0hclk";
		dmas = <0x68 0x04 0x68 0x05>;
		dma-names = "tx\0rx";
		resets = <0x0f 0x54>;
		reset-names = "tx-m";
		rockchip,grf = <0x20>;
		pinctrl-names = "default";
		pinctrl-0 = <0x6d 0x6e 0x6f 0x70>;
		#sound-dai-cells = <0x00>;
		status = "disabled";
	};

	i2s@fe430000 {
		compatible = "rockchip,rk3568-i2s-tdm";
		reg = <0x00 0xfe430000 0x00 0x1000>;
		interrupts = <0x00 0x37 0x04>;
		clocks = <0x0f 0x53 0x0f 0x57 0x0f 0x3c>;
		clock-names = "mclk_tx\0mclk_rx\0hclk";
		dmas = <0x68 0x06 0x68 0x07>;
		dma-names = "tx\0rx";
		resets = <0x0f 0x55 0x0f 0x56>;
		reset-names = "tx-m\0rx-m";
		rockchip,grf = <0x20>;
		#sound-dai-cells = <0x00>;
		status = "disabled";
	};

	pdm@fe440000 {
		compatible = "rockchip,rk3568-pdm";
		reg = <0x00 0xfe440000 0x00 0x1000>;
		interrupts = <0x00 0x4c 0x04>;
		clocks = <0x0f 0x5a 0x0f 0x59>;
		clock-names = "pdm_clk\0pdm_hclk";
		dmas = <0x68 0x09>;
		dma-names = "rx";
		pinctrl-0 = <0x71 0x72 0x73 0x74 0x75 0x76>;
		pinctrl-names = "default";
		resets = <0x0f 0x58>;
		reset-names = "pdm-m";
		#sound-dai-cells = <0x00>;
		status = "disabled";
	};

	spdif@fe460000 {
		compatible = "rockchip,rk3568-spdif";
		reg = <0x00 0xfe460000 0x00 0x1000>;
		interrupts = <0x00 0x66 0x04>;
		clock-names = "mclk\0hclk";
		clocks = <0x0f 0x5f 0x0f 0x5c>;
		dmas = <0x68 0x01>;
		dma-names = "tx";
		pinctrl-names = "default";
		pinctrl-0 = <0x77>;
		#sound-dai-cells = <0x00>;
		status = "disabled";
	};

	dma-controller@fe530000 {
		compatible = "arm,pl330\0arm,primecell";
		reg = <0x00 0xfe530000 0x00 0x4000>;
		interrupts = <0x00 0x0e 0x04 0x00 0x0d 0x04>;
		arm,pl330-periph-burst;
		clocks = <0x0f 0x10d>;
		clock-names = "apb_pclk";
		#dma-cells = <0x01>;
		phandle = <0x29>;
	};

	dma-controller@fe550000 {
		compatible = "arm,pl330\0arm,primecell";
		reg = <0x00 0xfe550000 0x00 0x4000>;
		interrupts = <0x00 0x10 0x04 0x00 0x0f 0x04>;
		arm,pl330-periph-burst;
		clocks = <0x0f 0x10d>;
		clock-names = "apb_pclk";
		#dma-cells = <0x01>;
		phandle = <0x68>;
	};

	i2c@fe5a0000 {
		compatible = "rockchip,rk3568-i2c\0rockchip,rk3399-i2c";
		reg = <0x00 0xfe5a0000 0x00 0x1000>;
		interrupts = <0x00 0x2f 0x04>;
		clocks = <0x0f 0x148 0x0f 0x147>;
		clock-names = "i2c\0pclk";
		pinctrl-0 = <0x78>;
		pinctrl-names = "default";
		#address-cells = <0x01>;
		#size-cells = <0x00>;
		status = "disabled";
	};

	i2c@fe5b0000 {
		compatible = "rockchip,rk3568-i2c\0rockchip,rk3399-i2c";
		reg = <0x00 0xfe5b0000 0x00 0x1000>;
		interrupts = <0x00 0x30 0x04>;
		clocks = <0x0f 0x14a 0x0f 0x149>;
		clock-names = "i2c\0pclk";
		pinctrl-0 = <0x79>;
		pinctrl-names = "default";
		#address-cells = <0x01>;
		#size-cells = <0x00>;
		status = "disabled";
	};

	i2c@fe5c0000 {
		compatible = "rockchip,rk3568-i2c\0rockchip,rk3399-i2c";
		reg = <0x00 0xfe5c0000 0x00 0x1000>;
		interrupts = <0x00 0x31 0x04>;
		clocks = <0x0f 0x14c 0x0f 0x14b>;
		clock-names = "i2c\0pclk";
		pinctrl-0 = <0x7a>;
		pinctrl-names = "default";
		#address-cells = <0x01>;
		#size-cells = <0x00>;
		status = "disabled";
	};

	i2c@fe5d0000 {
		compatible = "rockchip,rk3568-i2c\0rockchip,rk3399-i2c";
		reg = <0x00 0xfe5d0000 0x00 0x1000>;
		interrupts = <0x00 0x32 0x04>;
		clocks = <0x0f 0x14e 0x0f 0x14d>;
		clock-names = "i2c\0pclk";
		pinctrl-0 = <0x7b>;
		pinctrl-names = "default";
		#address-cells = <0x01>;
		#size-cells = <0x00>;
		status = "disabled";
	};

	i2c@fe5e0000 {
		compatible = "rockchip,rk3568-i2c\0rockchip,rk3399-i2c";
		reg = <0x00 0xfe5e0000 0x00 0x1000>;
		interrupts = <0x00 0x33 0x04>;
		clocks = <0x0f 0x150 0x0f 0x14f>;
		clock-names = "i2c\0pclk";
		pinctrl-0 = <0x7c>;
		pinctrl-names = "default";
		#address-cells = <0x01>;
		#size-cells = <0x00>;
		status = "disabled";
	};

	watchdog@fe600000 {
		compatible = "rockchip,rk3568-wdt\0snps,dw-wdt";
		reg = <0x00 0xfe600000 0x00 0x100>;
		interrupts = <0x00 0x95 0x04>;
		clocks = <0x0f 0x116 0x0f 0x115>;
		clock-names = "tclk\0pclk";
	};

	spi@fe610000 {
		compatible = "rockchip,rk3568-spi\0rockchip,rk3066-spi";
		reg = <0x00 0xfe610000 0x00 0x1000>;
		interrupts = <0x00 0x67 0x04>;
		clocks = <0x0f 0x152 0x0f 0x151>;
		clock-names = "spiclk\0apb_pclk";
		dmas = <0x29 0x14 0x29 0x15>;
		dma-names = "tx\0rx";
		pinctrl-names = "default";
		pinctrl-0 = <0x7d 0x7e 0x7f>;
		#address-cells = <0x01>;
		#size-cells = <0x00>;
		status = "disabled";
	};

	spi@fe620000 {
		compatible = "rockchip,rk3568-spi\0rockchip,rk3066-spi";
		reg = <0x00 0xfe620000 0x00 0x1000>;
		interrupts = <0x00 0x68 0x04>;
		clocks = <0x0f 0x154 0x0f 0x153>;
		clock-names = "spiclk\0apb_pclk";
		dmas = <0x29 0x16 0x29 0x17>;
		dma-names = "tx\0rx";
		pinctrl-names = "default";
		pinctrl-0 = <0x80 0x81 0x82>;
		#address-cells = <0x01>;
		#size-cells = <0x00>;
		status = "disabled";
	};

	spi@fe630000 {
		compatible = "rockchip,rk3568-spi\0rockchip,rk3066-spi";
		reg = <0x00 0xfe630000 0x00 0x1000>;
		interrupts = <0x00 0x69 0x04>;
		clocks = <0x0f 0x156 0x0f 0x155>;
		clock-names = "spiclk\0apb_pclk";
		dmas = <0x29 0x18 0x29 0x19>;
		dma-names = "tx\0rx";
		pinctrl-names = "default";
		pinctrl-0 = <0x83 0x84 0x85>;
		#address-cells = <0x01>;
		#size-cells = <0x00>;
		status = "disabled";
	};

	spi@fe640000 {
		compatible = "rockchip,rk3568-spi\0rockchip,rk3066-spi";
		reg = <0x00 0xfe640000 0x00 0x1000>;
		interrupts = <0x00 0x6a 0x04>;
		clocks = <0x0f 0x158 0x0f 0x157>;
		clock-names = "spiclk\0apb_pclk";
		dmas = <0x29 0x1a 0x29 0x1b>;
		dma-names = "tx\0rx";
		pinctrl-names = "default";
		pinctrl-0 = <0x86 0x87 0x88>;
		#address-cells = <0x01>;
		#size-cells = <0x00>;
		status = "disabled";
	};

	serial@fe650000 {
		compatible = "rockchip,rk3568-uart\0snps,dw-apb-uart";
		reg = <0x00 0xfe650000 0x00 0x100>;
		interrupts = <0x00 0x75 0x04>;
		clocks = <0x0f 0x11f 0x0f 0x11c>;
		clock-names = "baudclk\0apb_pclk";
		dmas = <0x29 0x02 0x29 0x03>;
		pinctrl-0 = <0x89>;
		pinctrl-names = "default";
		reg-io-width = <0x04>;
		reg-shift = <0x02>;
		status = "disabled";
	};

	serial@fe660000 {
		compatible = "rockchip,rk3568-uart\0snps,dw-apb-uart";
		reg = <0x00 0xfe660000 0x00 0x100>;
		interrupts = <0x00 0x76 0x04>;
		clocks = <0x0f 0x123 0x0f 0x120>;
		clock-names = "baudclk\0apb_pclk";
		dmas = <0x29 0x04 0x29 0x05>;
		pinctrl-0 = <0x8a>;
		pinctrl-names = "default";
		reg-io-width = <0x04>;
		reg-shift = <0x02>;
		status = "okay";
	};

	serial@fe670000 {
		compatible = "rockchip,rk3568-uart\0snps,dw-apb-uart";
		reg = <0x00 0xfe670000 0x00 0x100>;
		interrupts = <0x00 0x77 0x04>;
		clocks = <0x0f 0x127 0x0f 0x124>;
		clock-names = "baudclk\0apb_pclk";
		dmas = <0x29 0x06 0x29 0x07>;
		pinctrl-0 = <0x8b>;
		pinctrl-names = "default";
		reg-io-width = <0x04>;
		reg-shift = <0x02>;
		status = "disabled";
	};

	serial@fe680000 {
		compatible = "rockchip,rk3568-uart\0snps,dw-apb-uart";
		reg = <0x00 0xfe680000 0x00 0x100>;
		interrupts = <0x00 0x78 0x04>;
		clocks = <0x0f 0x12b 0x0f 0x128>;
		clock-names = "baudclk\0apb_pclk";
		dmas = <0x29 0x08 0x29 0x09>;
		pinctrl-0 = <0x8c>;
		pinctrl-names = "default";
		reg-io-width = <0x04>;
		reg-shift = <0x02>;
		status = "disabled";
	};

	serial@fe690000 {
		compatible = "rockchip,rk3568-uart\0snps,dw-apb-uart";
		reg = <0x00 0xfe690000 0x00 0x100>;
		interrupts = <0x00 0x79 0x04>;
		clocks = <0x0f 0x12f 0x0f 0x12c>;
		clock-names = "baudclk\0apb_pclk";
		dmas = <0x29 0x0a 0x29 0x0b>;
		pinctrl-0 = <0x8d>;
		pinctrl-names = "default";
		reg-io-width = <0x04>;
		reg-shift = <0x02>;
		status = "disabled";
	};

	serial@fe6a0000 {
		compatible = "rockchip,rk3568-uart\0snps,dw-apb-uart";
		reg = <0x00 0xfe6a0000 0x00 0x100>;
		interrupts = <0x00 0x7a 0x04>;
		clocks = <0x0f 0x133 0x0f 0x130>;
		clock-names = "baudclk\0apb_pclk";
		dmas = <0x29 0x0c 0x29 0x0d>;
		pinctrl-0 = <0x8e>;
		pinctrl-names = "default";
		reg-io-width = <0x04>;
		reg-shift = <0x02>;
		status = "disabled";
	};

	serial@fe6b0000 {
		compatible = "rockchip,rk3568-uart\0snps,dw-apb-uart";
		reg = <0x00 0xfe6b0000 0x00 0x100>;
		interrupts = <0x00 0x7b 0x04>;
		clocks = <0x0f 0x137 0x0f 0x134>;
		clock-names = "baudclk\0apb_pclk";
		dmas = <0x29 0x0e 0x29 0x0f>;
		pinctrl-0 = <0x8f>;
		pinctrl-names = "default";
		reg-io-width = <0x04>;
		reg-shift = <0x02>;
		status = "disabled";
	};

	serial@fe6c0000 {
		compatible = "rockchip,rk3568-uart\0snps,dw-apb-uart";
		reg = <0x00 0xfe6c0000 0x00 0x100>;
		interrupts = <0x00 0x7c 0x04>;
		clocks = <0x0f 0x13b 0x0f 0x138>;
		clock-names = "baudclk\0apb_pclk";
		dmas = <0x29 0x10 0x29 0x11>;
		pinctrl-0 = <0x90>;
		pinctrl-names = "default";
		reg-io-width = <0x04>;
		reg-shift = <0x02>;
		status = "disabled";
	};

	serial@fe6d0000 {
		compatible = "rockchip,rk3568-uart\0snps,dw-apb-uart";
		reg = <0x00 0xfe6d0000 0x00 0x100>;
		interrupts = <0x00 0x7d 0x04>;
		clocks = <0x0f 0x13f 0x0f 0x13c>;
		clock-names = "baudclk\0apb_pclk";
		dmas = <0x29 0x12 0x29 0x13>;
		pinctrl-0 = <0x91>;
		pinctrl-names = "default";
		reg-io-width = <0x04>;
		reg-shift = <0x02>;
		status = "disabled";
	};

	thermal-zones {

		cpu-thermal {
			polling-delay-passive = <0x64>;
			polling-delay = <0x3e8>;
			thermal-sensors = <0x92 0x00>;

			trips {

				cpu_alert0 {
					temperature = <0x11170>;
					hysteresis = <0x7d0>;
					type = "passive";
					phandle = <0x93>;
				};

				cpu_alert1 {
					temperature = <0x124f8>;
					hysteresis = <0x7d0>;
					type = "passive";
				};

				cpu_crit {
					temperature = <0x17318>;
					hysteresis = <0x7d0>;
					type = "critical";
				};
			};

			cooling-maps {

				map0 {
					trip = <0x93>;
					cooling-device = <0x0a 0xffffffff 0xffffffff 0x0b 0xffffffff 0xffffffff 0x0c 0xffffffff 0xffffffff 0x0d 0xffffffff 0xffffffff>;
				};
			};
		};

		gpu-thermal {
			polling-delay-passive = <0x14>;
			polling-delay = <0x3e8>;
			thermal-sensors = <0x92 0x01>;

			trips {

				gpu-threshold {
					temperature = <0x11170>;
					hysteresis = <0x7d0>;
					type = "passive";
				};

				gpu-target {
					temperature = <0x124f8>;
					hysteresis = <0x7d0>;
					type = "passive";
					phandle = <0x94>;
				};

				gpu-crit {
					temperature = <0x17318>;
					hysteresis = <0x7d0>;
					type = "critical";
				};
			};

			cooling-maps {

				map0 {
					trip = <0x94>;
					cooling-device = <0x95 0xffffffff 0xffffffff>;
				};
			};
		};
	};

	tsadc@fe710000 {
		compatible = "rockchip,rk3568-tsadc";
		reg = <0x00 0xfe710000 0x00 0x100>;
		interrupts = <0x00 0x73 0x04>;
		assigned-clocks = <0x0f 0x110 0x0f 0x111>;
		assigned-clock-rates = <0x1036640 0xaae60>;
		clocks = <0x0f 0x111 0x0f 0x10f>;
		clock-names = "tsadc\0apb_pclk";
		resets = <0x0f 0x181 0x0f 0x182 0x0f 0x1d7>;
		rockchip,grf = <0x20>;
		rockchip,hw-tshut-temp = <0x17318>;
		pinctrl-names = "init\0default\0sleep";
		pinctrl-0 = <0x96>;
		pinctrl-1 = <0x97>;
		pinctrl-2 = <0x96>;
		#thermal-sensor-cells = <0x01>;
		status = "okay";
		phandle = <0x92>;
	};

	saradc@fe720000 {
		compatible = "rockchip,rk3568-saradc\0rockchip,rk3399-saradc";
		reg = <0x00 0xfe720000 0x00 0x100>;
		interrupts = <0x00 0x5d 0x04>;
		clocks = <0x0f 0x113 0x0f 0x112>;
		clock-names = "saradc\0apb_pclk";
		resets = <0x0f 0x180>;
		reset-names = "saradc-apb";
		#io-channel-cells = <0x01>;
		status = "disabled";
	};

	pwm@fe6e0000 {
		compatible = "rockchip,rk3568-pwm\0rockchip,rk3328-pwm";
		reg = <0x00 0xfe6e0000 0x00 0x10>;
		clocks = <0x0f 0x15a 0x0f 0x159>;
		clock-names = "pwm\0pclk";
		pinctrl-0 = <0x98>;
		pinctrl-names = "default";
		#pwm-cells = <0x03>;
		status = "disabled";
	};

	pwm@fe6e0010 {
		compatible = "rockchip,rk3568-pwm\0rockchip,rk3328-pwm";
		reg = <0x00 0xfe6e0010 0x00 0x10>;
		clocks = <0x0f 0x15a 0x0f 0x159>;
		clock-names = "pwm\0pclk";
		pinctrl-0 = <0x99>;
		pinctrl-names = "default";
		#pwm-cells = <0x03>;
		status = "disabled";
	};

	pwm@fe6e0020 {
		compatible = "rockchip,rk3568-pwm\0rockchip,rk3328-pwm";
		reg = <0x00 0xfe6e0020 0x00 0x10>;
		clocks = <0x0f 0x15a 0x0f 0x159>;
		clock-names = "pwm\0pclk";
		pinctrl-0 = <0x9a>;
		pinctrl-names = "default";
		#pwm-cells = <0x03>;
		status = "disabled";
	};

	pwm@fe6e0030 {
		compatible = "rockchip,rk3568-pwm\0rockchip,rk3328-pwm";
		reg = <0x00 0xfe6e0030 0x00 0x10>;
		clocks = <0x0f 0x15a 0x0f 0x159>;
		clock-names = "pwm\0pclk";
		pinctrl-0 = <0x9b>;
		pinctrl-names = "default";
		#pwm-cells = <0x03>;
		status = "disabled";
	};

	pwm@fe6f0000 {
		compatible = "rockchip,rk3568-pwm\0rockchip,rk3328-pwm";
		reg = <0x00 0xfe6f0000 0x00 0x10>;
		clocks = <0x0f 0x15d 0x0f 0x15c>;
		clock-names = "pwm\0pclk";
		pinctrl-0 = <0x9c>;
		pinctrl-names = "default";
		#pwm-cells = <0x03>;
		status = "disabled";
	};

	pwm@fe6f0010 {
		compatible = "rockchip,rk3568-pwm\0rockchip,rk3328-pwm";
		reg = <0x00 0xfe6f0010 0x00 0x10>;
		clocks = <0x0f 0x15d 0x0f 0x15c>;
		clock-names = "pwm\0pclk";
		pinctrl-0 = <0x9d>;
		pinctrl-names = "default";
		#pwm-cells = <0x03>;
		status = "disabled";
	};

	pwm@fe6f0020 {
		compatible = "rockchip,rk3568-pwm\0rockchip,rk3328-pwm";
		reg = <0x00 0xfe6f0020 0x00 0x10>;
		clocks = <0x0f 0x15d 0x0f 0x15c>;
		clock-names = "pwm\0pclk";
		pinctrl-0 = <0x9e>;
		pinctrl-names = "default";
		#pwm-cells = <0x03>;
		status = "disabled";
	};

	pwm@fe6f0030 {
		compatible = "rockchip,rk3568-pwm\0rockchip,rk3328-pwm";
		reg = <0x00 0xfe6f0030 0x00 0x10>;
		clocks = <0x0f 0x15d 0x0f 0x15c>;
		clock-names = "pwm\0pclk";
		pinctrl-0 = <0x9f>;
		pinctrl-names = "default";
		#pwm-cells = <0x03>;
		status = "disabled";
	};

	pwm@fe700000 {
		compatible = "rockchip,rk3568-pwm\0rockchip,rk3328-pwm";
		reg = <0x00 0xfe700000 0x00 0x10>;
		clocks = <0x0f 0x160 0x0f 0x15f>;
		clock-names = "pwm\0pclk";
		pinctrl-0 = <0xa0>;
		pinctrl-names = "default";
		#pwm-cells = <0x03>;
		status = "disabled";
	};

	pwm@fe700010 {
		compatible = "rockchip,rk3568-pwm\0rockchip,rk3328-pwm";
		reg = <0x00 0xfe700010 0x00 0x10>;
		clocks = <0x0f 0x160 0x0f 0x15f>;
		clock-names = "pwm\0pclk";
		pinctrl-0 = <0xa1>;
		pinctrl-names = "default";
		#pwm-cells = <0x03>;
		status = "disabled";
	};

	pwm@fe700020 {
		compatible = "rockchip,rk3568-pwm\0rockchip,rk3328-pwm";
		reg = <0x00 0xfe700020 0x00 0x10>;
		clocks = <0x0f 0x160 0x0f 0x15f>;
		clock-names = "pwm\0pclk";
		pinctrl-0 = <0xa2>;
		pinctrl-names = "default";
		#pwm-cells = <0x03>;
		status = "okay";
		phandle = <0xb3>;
	};

	pwm@fe700030 {
		compatible = "rockchip,rk3568-pwm\0rockchip,rk3328-pwm";
		reg = <0x00 0xfe700030 0x00 0x10>;
		clocks = <0x0f 0x160 0x0f 0x15f>;
		clock-names = "pwm\0pclk";
		pinctrl-0 = <0xa3>;
		pinctrl-names = "default";
		#pwm-cells = <0x03>;
		status = "disabled";
	};

	phy@fe830000 {
		compatible = "rockchip,rk3568-naneng-combphy";
		reg = <0x00 0xfe830000 0x00 0x100>;
		clocks = <0x1f 0x22 0x0f 0x17d 0x0f 0x7f>;
		clock-names = "ref\0apb\0pipe";
		assigned-clocks = <0x1f 0x22>;
		assigned-clock-rates = <0x5f5e100>;
		resets = <0x0f 0x1c7>;
		reset-names = "phy";
		rockchip,pipe-grf = <0xa4>;
		rockchip,pipe-phy-grf = <0xa5>;
		#phy-cells = <0x01>;
		status = "okay";
		phandle = <0x10>;
	};

	phy@fe840000 {
		compatible = "rockchip,rk3568-naneng-combphy";
		reg = <0x00 0xfe840000 0x00 0x100>;
		clocks = <0x1f 0x25 0x0f 0x17e 0x0f 0x7f>;
		clock-names = "ref\0apb\0pipe";
		assigned-clocks = <0x1f 0x25>;
		assigned-clock-rates = <0x5f5e100>;
		resets = <0x0f 0x1c9>;
		reset-names = "phy";
		rockchip,pipe-grf = <0xa4>;
		rockchip,pipe-phy-grf = <0xa6>;
		#phy-cells = <0x01>;
		status = "okay";
		phandle = <0x12>;
	};

	phy@fe870000 {
		compatible = "rockchip,rk3568-csi-dphy";
		reg = <0x00 0xfe870000 0x00 0x10000>;
		clocks = <0x0f 0x179>;
		clock-names = "pclk";
		#phy-cells = <0x00>;
		resets = <0x0f 0x1ba>;
		reset-names = "apb";
		rockchip,grf = <0x20>;
		status = "disabled";
	};

	mipi-dphy@fe850000 {
		compatible = "rockchip,rk3568-dsi-dphy";
		reg = <0x00 0xfe850000 0x00 0x10000>;
		clock-names = "ref\0pclk";
		clocks = <0x1f 0x17 0x0f 0x17a>;
		#phy-cells = <0x00>;
		power-domains = <0x11 0x09>;
		reset-names = "apb";
		resets = <0x0f 0x1bb>;
		status = "okay";
		phandle = <0x4f>;
	};

	mipi-dphy@fe860000 {
		compatible = "rockchip,rk3568-dsi-dphy";
		reg = <0x00 0xfe860000 0x00 0x10000>;
		clock-names = "ref\0pclk";
		clocks = <0x1f 0x19 0x0f 0x17b>;
		#phy-cells = <0x00>;
		power-domains = <0x11 0x09>;
		reset-names = "apb";
		resets = <0x0f 0x1bc>;
		status = "disabled";
		phandle = <0x59>;
	};

	usb2phy@fe8a0000 {
		compatible = "rockchip,rk3568-usb2phy";
		reg = <0x00 0xfe8a0000 0x00 0x10000>;
		clocks = <0x1f 0x13>;
		clock-names = "phyclk";
		clock-output-names = "clk_usbphy0_480m";
		interrupts = <0x00 0x87 0x04>;
		rockchip,usbgrf = <0xa7>;
		#clock-cells = <0x00>;
		status = "okay";
		phandle = <0x14>;

		host-port {
			#phy-cells = <0x00>;
			status = "disabled";
			phandle = <0x15>;
		};

		otg-port {
			#phy-cells = <0x00>;
			status = "okay";
			phandle = <0x13>;
		};
	};

	usb2phy@fe8b0000 {
		compatible = "rockchip,rk3568-usb2phy";
		reg = <0x00 0xfe8b0000 0x00 0x10000>;
		clocks = <0x1f 0x15>;
		clock-names = "phyclk";
		clock-output-names = "clk_usbphy1_480m";
		interrupts = <0x00 0x88 0x04>;
		rockchip,usbgrf = <0xa8>;
		#clock-cells = <0x00>;
		status = "disabled";

		host-port {
			#phy-cells = <0x00>;
			status = "disabled";
			phandle = <0x17>;
		};

		otg-port {
			#phy-cells = <0x00>;
			status = "disabled";
			phandle = <0x16>;
		};
	};

	pinctrl {
		compatible = "rockchip,rk3568-pinctrl";
		rockchip,grf = <0x20>;
		rockchip,pmu = <0xa9>;
		#address-cells = <0x02>;
		#size-cells = <0x02>;
		ranges;
		phandle = <0xaa>;

		gpio@fdd60000 {
			compatible = "rockchip,gpio-bank";
			reg = <0x00 0xfdd60000 0x00 0x100>;
			interrupts = <0x00 0x21 0x04>;
			clocks = <0x1f 0x2e 0x1f 0x0c>;
			gpio-controller;
			gpio-ranges = <0xaa 0x00 0x00 0x20>;
			#gpio-cells = <0x02>;
			interrupt-controller;
			#interrupt-cells = <0x02>;
			phandle = <0x23>;
		};

		gpio@fe740000 {
			compatible = "rockchip,gpio-bank";
			reg = <0x00 0xfe740000 0x00 0x100>;
			interrupts = <0x00 0x22 0x04>;
			clocks = <0x0f 0x163 0x0f 0x164>;
			gpio-controller;
			gpio-ranges = <0xaa 0x00 0x20 0x20>;
			#gpio-cells = <0x02>;
			interrupt-controller;
			#interrupt-cells = <0x02>;
		};

		gpio@fe750000 {
			compatible = "rockchip,gpio-bank";
			reg = <0x00 0xfe750000 0x00 0x100>;
			interrupts = <0x00 0x23 0x04>;
			clocks = <0x0f 0x165 0x0f 0x166>;
			gpio-controller;
			gpio-ranges = <0xaa 0x00 0x40 0x20>;
			#gpio-cells = <0x02>;
			interrupt-controller;
			#interrupt-cells = <0x02>;
		};

		gpio@fe760000 {
			compatible = "rockchip,gpio-bank";
			reg = <0x00 0xfe760000 0x00 0x100>;
			interrupts = <0x00 0x24 0x04>;
			clocks = <0x0f 0x167 0x0f 0x168>;
			gpio-controller;
			gpio-ranges = <0xaa 0x00 0x60 0x20>;
			#gpio-cells = <0x02>;
			interrupt-controller;
			#interrupt-cells = <0x02>;
			phandle = <0x53>;
		};

		gpio@fe770000 {
			compatible = "rockchip,gpio-bank";
			reg = <0x00 0xfe770000 0x00 0x100>;
			interrupts = <0x00 0x25 0x04>;
			clocks = <0x0f 0x169 0x0f 0x16a>;
			gpio-controller;
			gpio-ranges = <0xaa 0x00 0x80 0x20>;
			#gpio-cells = <0x02>;
			interrupt-controller;
			#interrupt-cells = <0x02>;
		};

		pcfg-pull-up {
			bias-pull-up;
			phandle = <0xad>;
		};

		pcfg-pull-none {
			bias-disable;
			phandle = <0xab>;
		};

		pcfg-pull-none-drv-level-1 {
			bias-disable;
			drive-strength = <0x01>;
			phandle = <0xaf>;
		};

		pcfg-pull-none-drv-level-2 {
			bias-disable;
			drive-strength = <0x02>;
			phandle = <0xae>;
		};

		pcfg-pull-none-drv-level-3 {
			bias-disable;
			drive-strength = <0x03>;
			phandle = <0xb2>;
		};

		pcfg-pull-up-drv-level-1 {
			bias-pull-up;
			drive-strength = <0x01>;
			phandle = <0xb1>;
		};

		pcfg-pull-up-drv-level-2 {
			bias-pull-up;
			drive-strength = <0x02>;
			phandle = <0xac>;
		};

		pcfg-pull-none-smt {
			bias-disable;
			input-schmitt-enable;
			phandle = <0xb0>;
		};

		acodec {
		};

		audiopwm {
		};

		bt656 {
		};

		bt1120 {
		};

		cam {
		};

		can0 {
		};

		can1 {
		};

		can2 {
		};

		cif {
		};

		clk32k {

			clk32k-out0 {
				rockchip,pins = <0x00 0x08 0x02 0xab>;
				phandle = <0x0e>;
			};
		};

		cpu {
		};

		ebc {
		};

		edpdp {
		};

		emmc {

			emmc-bus8 {
				rockchip,pins = <0x01 0x0c 0x01 0xac 0x01 0x0d 0x01 0xac 0x01 0x0e 0x01 0xac 0x01 0x0f 0x01 0xac 0x01 0x10 0x01 0xac 0x01 0x11 0x01 0xac 0x01 0x12 0x01 0xac 0x01 0x13 0x01 0xac>;
				phandle = <0x64>;
			};

			emmc-clk {
				rockchip,pins = <0x01 0x15 0x01 0xac>;
				phandle = <0x65>;
			};

			emmc-cmd {
				rockchip,pins = <0x01 0x14 0x01 0xac>;
				phandle = <0x66>;
			};

			emmc-datastrobe {
				rockchip,pins = <0x01 0x16 0x01 0xab>;
				phandle = <0x67>;
			};
		};

		eth0 {
		};

		eth1 {
		};

		flash {
		};

		fspi {

			fspi-pins {
				rockchip,pins = <0x01 0x18 0x01 0xab 0x01 0x1b 0x01 0xab 0x01 0x19 0x01 0xab 0x01 0x1a 0x01 0xab 0x01 0x17 0x02 0xab 0x01 0x1c 0x01 0xab>;
				phandle = <0x63>;
			};
		};

		gmac0 {
		};

		gmac1 {
		};

		gpu {
		};

		hdmitx {

			hdmitxm0-cec {
				rockchip,pins = <0x04 0x19 0x01 0xab>;
				phandle = <0x5c>;
			};

			hdmitx-scl {
				rockchip,pins = <0x04 0x17 0x01 0xab>;
				phandle = <0x5a>;
			};

			hdmitx-sda {
				rockchip,pins = <0x04 0x18 0x01 0xab>;
				phandle = <0x5b>;
			};
		};

		i2c0 {

			i2c0-xfer {
				rockchip,pins = <0x00 0x09 0x01 0xb0 0x00 0x0a 0x01 0xb0>;
				phandle = <0x21>;
			};
		};

		i2c1 {

			i2c1-xfer {
				rockchip,pins = <0x00 0x0b 0x01 0xb0 0x00 0x0c 0x01 0xb0>;
				phandle = <0x78>;
			};
		};

		i2c2 {

			i2c2m0-xfer {
				rockchip,pins = <0x00 0x0d 0x01 0xb0 0x00 0x0e 0x01 0xb0>;
				phandle = <0x79>;
			};
		};

		i2c3 {

			i2c3m0-xfer {
				rockchip,pins = <0x01 0x01 0x01 0xb0 0x01 0x00 0x01 0xb0>;
				phandle = <0x7a>;
			};
		};

		i2c4 {

			i2c4m0-xfer {
				rockchip,pins = <0x04 0x0b 0x01 0xb0 0x04 0x0a 0x01 0xb0>;
				phandle = <0x7b>;
			};
		};

		i2c5 {

			i2c5m0-xfer {
				rockchip,pins = <0x03 0x0b 0x04 0xb0 0x03 0x0c 0x04 0xb0>;
				phandle = <0x7c>;
			};
		};

		i2s1 {

			i2s1m0-lrcktx {
				rockchip,pins = <0x01 0x05 0x01 0xab>;
				phandle = <0x6a>;
			};

			i2s1m0-mclk {
				rockchip,pins = <0x01 0x02 0x01 0xab>;
				phandle = <0x25>;
			};

			i2s1m0-sclktx {
				rockchip,pins = <0x01 0x03 0x01 0xab>;
				phandle = <0x69>;
			};

			i2s1m0-sdi0 {
				rockchip,pins = <0x01 0x0b 0x01 0xab>;
				phandle = <0x6b>;
			};

			i2s1m0-sdo0 {
				rockchip,pins = <0x01 0x07 0x01 0xab>;
				phandle = <0x6c>;
			};
		};

		i2s2 {

			i2s2m0-lrcktx {
				rockchip,pins = <0x02 0x13 0x01 0xab>;
				phandle = <0x6e>;
			};

			i2s2m0-sclktx {
				rockchip,pins = <0x02 0x12 0x01 0xab>;
				phandle = <0x6d>;
			};

			i2s2m0-sdi {
				rockchip,pins = <0x02 0x15 0x01 0xab>;
				phandle = <0x6f>;
			};

			i2s2m0-sdo {
				rockchip,pins = <0x02 0x14 0x01 0xab>;
				phandle = <0x70>;
			};
		};

		i2s3 {
		};

		isp {
		};

		jtag {
		};

		lcdc {
		};

		mcu {
		};

		npu {
		};

		pcie20 {
		};

		pcie30x1 {
		};

		pcie30x2 {
		};

		pdm {

			pdmm0-clk {
				rockchip,pins = <0x01 0x06 0x03 0xab>;
				phandle = <0x71>;
			};

			pdmm0-clk1 {
				rockchip,pins = <0x01 0x04 0x03 0xab>;
				phandle = <0x72>;
			};

			pdmm0-sdi0 {
				rockchip,pins = <0x01 0x0b 0x02 0xab>;
				phandle = <0x73>;
			};

			pdmm0-sdi1 {
				rockchip,pins = <0x01 0x0a 0x03 0xab>;
				phandle = <0x74>;
			};

			pdmm0-sdi2 {
				rockchip,pins = <0x01 0x09 0x03 0xab>;
				phandle = <0x75>;
			};

			pdmm0-sdi3 {
				rockchip,pins = <0x01 0x08 0x03 0xab>;
				phandle = <0x76>;
			};
		};

		pmic {

			pmic-int {
				rockchip,pins = <0x00 0x03 0x00 0xad>;
				phandle = <0x24>;
			};
		};

		pmu {
		};

		pwm0 {

			pwm0m0-pins {
				rockchip,pins = <0x00 0x0f 0x01 0xab>;
				phandle = <0x2b>;
			};
		};

		pwm1 {

			pwm1m0-pins {
				rockchip,pins = <0x00 0x10 0x01 0xab>;
				phandle = <0x2c>;
			};
		};

		pwm2 {

			pwm2m0-pins {
				rockchip,pins = <0x00 0x11 0x01 0xab>;
				phandle = <0x2d>;
			};
		};

		pwm3 {

			pwm3-pins {
				rockchip,pins = <0x00 0x12 0x01 0xab>;
				phandle = <0x2e>;
			};
		};

		pwm4 {

			pwm4-pins {
				rockchip,pins = <0x00 0x13 0x01 0xab>;
				phandle = <0x98>;
			};
		};

		pwm5 {

			pwm5-pins {
				rockchip,pins = <0x00 0x14 0x01 0xab>;
				phandle = <0x99>;
			};
		};

		pwm6 {

			pwm6-pins {
				rockchip,pins = <0x00 0x15 0x01 0xab>;
				phandle = <0x9a>;
			};
		};

		pwm7 {

			pwm7-pins {
				rockchip,pins = <0x00 0x16 0x01 0xab>;
				phandle = <0x9b>;
			};
		};

		pwm8 {

			pwm8m0-pins {
				rockchip,pins = <0x03 0x09 0x05 0xab>;
				phandle = <0x9c>;
			};
		};

		pwm9 {

			pwm9m0-pins {
				rockchip,pins = <0x03 0x0a 0x05 0xab>;
				phandle = <0x9d>;
			};
		};

		pwm10 {

			pwm10m0-pins {
				rockchip,pins = <0x03 0x0d 0x05 0xab>;
				phandle = <0x9e>;
			};
		};

		pwm11 {

			pwm11m0-pins {
				rockchip,pins = <0x03 0x0e 0x05 0xab>;
				phandle = <0x9f>;
			};
		};

		pwm12 {

			pwm12m0-pins {
				rockchip,pins = <0x03 0x0f 0x02 0xab>;
				phandle = <0xa0>;
			};
		};

		pwm13 {

			pwm13m0-pins {
				rockchip,pins = <0x03 0x10 0x02 0xab>;
				phandle = <0xa1>;
			};
		};

		pwm14 {

			pwm14m0-pins {
				rockchip,pins = <0x03 0x14 0x01 0xab>;
				phandle = <0xa2>;
			};
		};

		pwm15 {

			pwm15m0-pins {
				rockchip,pins = <0x03 0x15 0x01 0xab>;
				phandle = <0xa3>;
			};
		};

		refclk {
		};

		sata {
		};

		sata0 {
		};

		sata1 {
		};

		sata2 {
		};

		scr {
		};

		sdmmc0 {

			sdmmc0-bus4 {
				rockchip,pins = <0x01 0x1d 0x01 0xac 0x01 0x1e 0x01 0xac 0x01 0x1f 0x01 0xac 0x02 0x00 0x01 0xac>;
				phandle = <0x5e>;
			};

			sdmmc0-clk {
				rockchip,pins = <0x02 0x02 0x01 0xac>;
				phandle = <0x5f>;
			};

			sdmmc0-cmd {
				rockchip,pins = <0x02 0x01 0x01 0xac>;
				phandle = <0x60>;
			};

			sdmmc0-det {
				rockchip,pins = <0x00 0x04 0x01 0xad>;
				phandle = <0x61>;
			};
		};

		sdmmc1 {
		};

		sdmmc2 {
		};

		spdif {

			spdifm0-tx {
				rockchip,pins = <0x01 0x04 0x04 0xab>;
				phandle = <0x77>;
			};
		};

		spi0 {

			spi0m0-pins {
				rockchip,pins = <0x00 0x0d 0x02 0xab 0x00 0x15 0x02 0xab 0x00 0x0e 0x02 0xab>;
				phandle = <0x7f>;
			};

			spi0m0-cs0 {
				rockchip,pins = <0x00 0x16 0x02 0xab>;
				phandle = <0x7d>;
			};

			spi0m0-cs1 {
				rockchip,pins = <0x00 0x14 0x02 0xab>;
				phandle = <0x7e>;
			};
		};

		spi1 {

			spi1m0-pins {
				rockchip,pins = <0x02 0x0d 0x03 0xab 0x02 0x0e 0x03 0xab 0x02 0x0f 0x04 0xab>;
				phandle = <0x82>;
			};

			spi1m0-cs0 {
				rockchip,pins = <0x02 0x10 0x04 0xab>;
				phandle = <0x80>;
			};

			spi1m0-cs1 {
				rockchip,pins = <0x02 0x16 0x03 0xab>;
				phandle = <0x81>;
			};
		};

		spi2 {

			spi2m0-pins {
				rockchip,pins = <0x02 0x11 0x04 0xab 0x02 0x12 0x04 0xab 0x02 0x13 0x04 0xab>;
				phandle = <0x85>;
			};

			spi2m0-cs0 {
				rockchip,pins = <0x02 0x14 0x04 0xab>;
				phandle = <0x83>;
			};

			spi2m0-cs1 {
				rockchip,pins = <0x02 0x15 0x04 0xab>;
				phandle = <0x84>;
			};
		};

		spi3 {

			spi3m0-pins {
				rockchip,pins = <0x04 0x0b 0x04 0xab 0x04 0x08 0x04 0xab 0x04 0x0a 0x04 0xab>;
				phandle = <0x88>;
			};

			spi3m0-cs0 {
				rockchip,pins = <0x04 0x06 0x04 0xab>;
				phandle = <0x86>;
			};

			spi3m0-cs1 {
				rockchip,pins = <0x04 0x07 0x04 0xab>;
				phandle = <0x87>;
			};
		};

		tsadc {

			tsadc-shutorg {
				rockchip,pins = <0x00 0x01 0x02 0xab>;
				phandle = <0x97>;
			};

			tsadc-pin {
				rockchip,pins = <0x00 0x01 0x00 0xab>;
				phandle = <0x96>;
			};
		};

		uart0 {

			uart0-xfer {
				rockchip,pins = <0x00 0x10 0x03 0xad 0x00 0x11 0x03 0xad>;
				phandle = <0x2a>;
			};
		};

		uart1 {

			uart1m0-xfer {
				rockchip,pins = <0x02 0x0b 0x02 0xad 0x02 0x0c 0x02 0xad>;
				phandle = <0x89>;
			};
		};

		uart2 {

			uart2m0-xfer {
				rockchip,pins = <0x00 0x18 0x01 0xad 0x00 0x19 0x01 0xad>;
				phandle = <0x8a>;
			};
		};

		uart3 {

			uart3m0-xfer {
				rockchip,pins = <0x01 0x00 0x02 0xad 0x01 0x01 0x02 0xad>;
				phandle = <0x8b>;
			};
		};

		uart4 {

			uart4m0-xfer {
				rockchip,pins = <0x01 0x04 0x02 0xad 0x01 0x06 0x02 0xad>;
				phandle = <0x8c>;
			};
		};

		uart5 {

			uart5m0-xfer {
				rockchip,pins = <0x02 0x01 0x03 0xad 0x02 0x02 0x03 0xad>;
				phandle = <0x8d>;
			};
		};

		uart6 {

			uart6m0-xfer {
				rockchip,pins = <0x02 0x03 0x03 0xad 0x02 0x04 0x03 0xad>;
				phandle = <0x8e>;
			};
		};

		uart7 {

			uart7m0-xfer {
				rockchip,pins = <0x02 0x05 0x03 0xad 0x02 0x06 0x03 0xad>;
				phandle = <0x8f>;
			};
		};

		uart8 {

			uart8m0-xfer {
				rockchip,pins = <0x02 0x16 0x02 0xad 0x02 0x15 0x03 0xad>;
				phandle = <0x90>;
			};
		};

		uart9 {

			uart9m0-xfer {
				rockchip,pins = <0x02 0x07 0x03 0xad 0x02 0x08 0x03 0xad>;
				phandle = <0x91>;
			};
		};

		vop {
		};

		spi0-hs {
		};

		spi1-hs {
		};

		spi2-hs {
		};

		spi3-hs {
		};

		gmac-txd-level3 {
		};

		gmac-txc-level2 {
		};

		usb {

			vcc5v0-usb-host-en {
				rockchip,pins = <0x03 0x10 0x00 0xab>;
			};
		};

		vcc_sd {

			vcc-sd-h {
				rockchip,pins = <0x00 0x05 0x00 0xab>;
				phandle = <0xb5>;
			};
		};

		lcd {

			lcd-rst-gpio {
				rockchip,pins = <0x03 0x13 0x00 0xab>;
				phandle = <0x54>;
			};

			lcd-enable-gpio {
				rockchip,pins = <0x03 0x09 0x00 0xab>;
				phandle = <0x55>;
			};
		};
	};

	chosen {
		stdout-path = "serial2:1500000n8";
		bootargs = "console=tty0 console=ttyS2,1500000n8";
	};

	backlight {
		compatible = "pwm-backlight";
		power-supply = <0x26>;
		pwms = <0xb3 0x00 0x61a8 0x00>;
		brightness-levels = <0x00 0x14 0x14 0x15 0x15 0x16 0x16 0x17 0x17 0x18 0x18 0x19 0x19 0x1a 0x1a 0x1b 0x1b 0x1c 0x1c 0x1d 0x1d 0x1e 0x1e 0x1f 0x1f 0x20 0x20 0x21 0x21 0x22 0x22 0x23 0x23 0x24 0x24 0x25 0x25 0x26 0x26 0x27 0x28 0x29 0x2a 0x2b 0x2c 0x2d 0x2e 0x2f 0x30 0x31 0x32 0x33 0x34 0x35 0x36 0x37 0x38 0x39 0x3a 0x3b 0x3c 0x3d 0x3e 0x3f 0x40 0x41 0x42 0x43 0x44 0x45 0x46 0x47 0x48 0x49 0x4a 0x4b 0x4c 0x4d 0x4e 0x4f 0x50 0x51 0x52 0x53 0x54 0x55 0x56 0x57 0x58 0x59 0x5a 0x5b 0x5c 0x5d 0x5e 0x5f 0x60 0x61 0x62 0x63 0x64 0x65 0x66 0x67 0x68 0x69 0x6a 0x6b 0x6c 0x6d 0x6e 0x6f 0x70 0x71 0x72 0x73 0x74 0x75 0x76 0x77 0x78 0x79 0x7a 0x7b 0x7c 0x7d 0x7e 0x7f 0x80 0x81 0x82 0x83 0x84 0x85 0x86 0x87 0x88 0x89 0x8a 0x8b 0x8c 0x8d 0x8e 0x8f 0x90 0x91 0x92 0x93 0x94 0x95 0x96 0x97 0x98 0x99 0x9a 0x9b 0x9c 0x9d 0x9e 0x9f 0xa0 0xa1 0xa2 0xa3 0xa4 0xa5 0xa6 0xa7 0xa8 0xa9 0xaa 0xab 0xac 0xad 0xae 0xaf 0xb0 0xb1 0xb2 0xb3 0xb4 0xb5 0xb6 0xb7 0xb8 0xb9 0xba 0xbb 0xbc 0xbd 0xbe 0xbf 0xc0 0xc1 0xc2 0xc3 0xc4 0xc5 0xc6 0xc7 0xc8 0xc9 0xca 0xcb 0xcc 0xcd 0xce 0xcf 0xd0 0xd1 0xd2 0xd3 0xd4 0xd5 0xd6 0xd7 0xd8 0xd9 0xda 0xdb 0xdc 0xdd 0xde 0xdf 0xe0 0xe1 0xe2 0xe3 0xe4 0xe5 0xe6 0xe7 0xe8 0xe9 0xea 0xeb 0xec 0xed 0xee 0xef 0xf0 0xf1 0xf2 0xf3 0xf4 0xf5 0xf6 0xf7 0xf8 0xf9 0xfa 0xfb 0xfc 0xfd 0xfe 0xff>;
		default-brightness-level = <0x80>;
		phandle = <0x52>;
	};

	battery {
		compatible = "simple-battery";
		charge-full-design-microamp-hours = <0x5b8d80>;
		charge-term-current-microamp = <0x493e0>;
		constant-charge-current-max-microamp = <0x1e8480>;
		constant-charge-voltage-max-microvolt = <0x419ce0>;
		voltage-max-design-microvolt = <0x3f2410>;
		voltage-min-design-microvolt = <0x33e140>;
		ocv-capacity-celsius = <0x14>;
		ocv-capacity-table-0 = <0x3f2410 0x64 0x3e4d38 0x5f 0x3def78 0x5a 0x3db4e0 0x55 0x3d7e30 0x50 0x3d5720 0x4b 0x3d2070 0x46 0x3c9ba0 0x41 0x3c0730 0x3c 0x3b9200 0x37 0x3b2c70 0x32 0x3ada68 0x2d 0x3aa3b8 0x28 0x3a6150 0x23 0x39ffa8 0x1e 0x397ec0 0x19 0x38fdd8 0x14 0x384640 0x0f 0x374088 0x0a 0x3636e8 0x05 0x33e140 0x00>;
		phandle = <0x28>;
	};

	vdd-usbc-regulator {
		compatible = "regulator-fixed";
		regulator-name = "vdd_usbc";
		regulator-always-on;
		regulator-boot-on;
		regulator-min-microvolt = <0x4c4b40>;
		regulator-max-microvolt = <0x4c4b40>;
		phandle = <0xb4>;
	};

	regulator-vcc3v3-sys {
		compatible = "regulator-fixed";
		regulator-name = "vcc3v3_sys";
		regulator-always-on;
		regulator-boot-on;
		regulator-min-microvolt = <0x325aa0>;
		regulator-max-microvolt = <0x325aa0>;
		vin-supply = <0x22>;
		phandle = <0x26>;
	};

	regulator-vcc-lcd {
		compatible = "regulator-fixed";
		regulator-name = "vcc_lcd";
		regulator-always-on;
		regulator-boot-on;
		regulator-min-microvolt = <0x325aa0>;
		regulator-max-microvolt = <0x325aa0>;
		vin-supply = <0x26>;
		phandle = <0x56>;
	};

	regulator-vcc5v0-sys {
		compatible = "regulator-fixed";
		regulator-name = "vcc5v0_sys";
		regulator-always-on;
		regulator-boot-on;
		regulator-min-microvolt = <0x4c4b40>;
		regulator-max-microvolt = <0x4c4b40>;
		vin-supply = <0xb4>;
		phandle = <0x22>;
	};

	vcc3v3_sd {
		compatible = "regulator-fixed";
		gpio = <0x23 0x05 0x01>;
		pinctrl-names = "default";
		pinctrl-0 = <0xb5>;
		regulator-boot-on;
		regulator-name = "vcc3v3_sd";
		regulator-min-microvolt = <0x325aa0>;
		regulator-max-microvolt = <0x325aa0>;
		vin-supply = <0x26>;
		phandle = <0x62>;
	};
};
